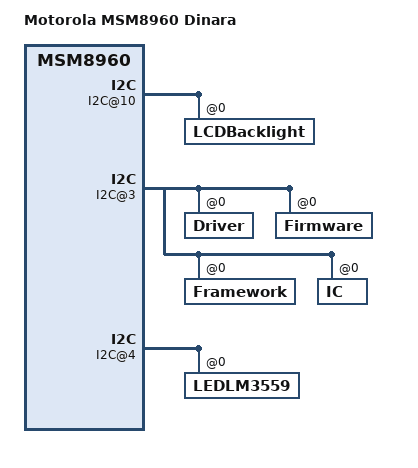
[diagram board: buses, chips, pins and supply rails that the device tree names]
/* Copyright (c) 2013 Motorola Mobility LLC. All rights reserved.
 *
 * This program is free software; you can redistribute it and/or modify
 * it under the terms of the GNU General Public License version 2 and
 * only version 2 as published by the Free Software Foundation.
 *
 * This program is distributed in the hope that it will be useful,
 * but WITHOUT ANY WARRANTY; without even the implied warranty of
 * MERCHANTABILITY or FITNESS FOR A PARTICULAR PURPOSE.  See the
 * GNU General Public License for more details.
 */

/dts-v1/;

/include/ "skeleton.dtsi"

/include/ "msm8960.dtsi"

/include/ "msm8960-motref.dtsi"

/include/ "msm8960-motref-pinmux.dtsi"

/ {
	model = "Motorola MSM8960 Dinara";
	compatible = "mmi,msm8960-qinara";

	mmi,product = "mmi,msm8960-dinara";

	mmi,dt_revision = <2>;

	Aliases@0 {
	};

	Machine@0 {
	};

};


/ {

	Aliases@0 {
	};

	Chosen@0 {
		batt_eprom_gpio = <0x5d>;
		emu_id_activehigh = <0x01>;
		emu_id_flt_activehigh = <0x01>;
		emu_id_flt_gpio = <0xaa>;
		emu_id_mpp_gpio = <0xcd>;
		factory_kill_disable = <0x00>;
		factory_kill_gpio = <0x0000004b>;
		formfactor = <0x00000003>;
		last_compat_version = <0x01330684>;
		product = <0x000015ff>;
		version = <0x0133068b>;
	};

	Machine@0 {
	};

	System@0 {

		ClockTree@0 {
			class = [436c6f636b5472656500];
			type = <0x001e0014>;

			Clock@0 {
				class = [5175616c636f6d6d436c6f636b54726565436c6f636b00];
				clock = <0x000c>;
				clockname = [636f72655f636c6b00];
				deviceid = [6d736d5f73657269616c5f68736c2e3500];
				type = <0x001e0015>;
			};

			Clock@1 {
				class = [5175616c636f6d6d436c6f636b54726565436c6f636b00];
				clock = <0x000e>;
				clockname = [69666163655f636c6b00];
				deviceid = [6d736d5f73657269616c5f68736c2e3500];
				type = <0x001e0015>;
			};

			Clock@2 {
				class = [5175616c636f6d6d436c6f636b54726565436c6f636b00];
				clock = <0x0025>;
				clockname = [63616d5f636c6b00];
				deviceid = [342d3030333600];
				type = <0x001e0015>;
			};

			Clock@3 {
				class = [5175616c636f6d6d436c6f636b54726565436c6f636b00];
				clock = <0x0024>;
				clockname = [63616d5f636c6b00];
				deviceid = [342d3030343800];
				type = <0x001e0015>;
			};

			Clock@4 { /* gsbi4_uart_clk, core_clk, msm_serial_hs.1 */
				class = [5175616c636f6d6d436c6f636b54726565436c6f636b00];
				clock = <0x0009>;
				clockname = [636f72655f636c6b00];
				deviceid = [6d736d5f73657269616c5f68732e3100];
				type = <0x001e0015>;
			};

			Clock@5 { /* gsbi4_p_clk, iface_clk, msm_serial_hs.1 */
				class = [5175616c636f6d6d436c6f636b54726565436c6f636b00];
				clock = <0x000b>;
				clockname = [69666163655f636c6b00];
				deviceid = [6d736d5f73657269616c5f68732e3100];
				type = <0x001e0015>;
			};

			Clock@6 { /* gsbi4_p_clk, iface_clk, qup_i2c.4 */
				class = [5175616c636f6d6d436c6f636b54726565436c6f636b00];
				clock = <0x000b>;
				clockname = [69666163655f636c6b00];
				deviceid = [7175705f6932632e3400];
				type = <0x001e0015>;
			};
		};

		EMUDetection@0 {
			accy-support = <0x00>;
			class = [5175616c636f6d6d5f454d555f446574656374696f6e00];
			ic-type = <0x00>;
			type = <0x0000001d>;
			uart-gsbi = <0x04>;
			usb-otg-vreg = [383932315f7573625f6f746700];
			vdd-vreg = [454d555f504f57455200];
			vdd-vreg-mv = <0x00286f90>;

			Gpio-alt-mode@0 {
				class = [4750494f00];
				gpio-info = <0x0211>;
				pin-name = [53454d555f414c545f4d4f44455f454e5f4750494f00];
				pmic-gpio-cfg = [010000050603000001];
				pmic-gpio-cfg-alt = [010001050601000000];
				type = <0x001e0010>;
			};

			Gpio-dminus@0 {
				class = [4750494f00];
				gpio-info = <0x0215>;
				pin-name = [444d494e55535f4750494f00];
				pmic-gpio-cfg = [010000010602010000];
				pmic-gpio-cfg-alt = [020000040603000000];
				type = <0x001e0010>;
			};

			Gpio-dplus@0 {
				class = [4750494f00];
				gpio-info = <0x0229>;
				pin-name = [44504c55535f4750494f00];
				pmic-gpio-cfg = [020000010602010000];
				pmic-gpio-cfg-alt = [020000000603000000];
				type = <0x001e0010>;
			};

			Gpio-id-en@0 {
				class = [4750494f00];
				gpio-info = <0x0309>;
				pin-name = [454d555f49445f454e5f4750494f00];
				pmic-mpp-cfg = [000400];
				pmic-mpp-cfg-alt = [010401];
				type = <0x001e0010>;
			};

			Gpio-id@0 {
				class = [4750494f00];
				gpio-info = <0x030a>;
				pin-name = [454d555f49445f4750494f00];
				pmic-mpp-cfg = [030200];
				type = <0x001e0010>;
			};

			Gpio-mux-ctrl0@0 {
				class = [4750494f00];
				gpio-info = <0x016b>;
				msm-gpio-cfg = <0x00030300>;
				pin-name = [454d555f4d55585f4354524c305f4750494f00];
				type = <0x001e0010>;
			};

			Gpio-mux-ctrl1@0 {
				class = [4750494f00];
				gpio-info = <0x0160>;
				msm-gpio-cfg = <0x00030100>;
				pin-name = [454d555f4d55585f4354524c315f4750494f00];
				type = <0x001e0010>;
			};

			Gpio-ppd-det@0 {
				class = [4750494f00];
				gpio-info = <0x0223>;
				pin-name = [53454d555f5050445f4445545f4750494f00];
				pmic-gpio-cfg = [020000050603000000];
				type = <0x001e0010>;
			};

			Gpio-sci-out@0 {
				class = [4750494f00];
				gpio-info = <0x015a>;
				msm-gpio-cfg = <0x00030000>;
				pin-name = [454d555f5343495f4f55545f4750494f00];
				type = <0x001e0010>;
			};

			Gpio-uart-rx-pair@0 {
				class = [4750494f00];
				gpio-info = <0x022a>;
				pin-name = [52585f504149525f4750494f00];
				pmic-gpio-cfg = [010000010202010000];
				pmic-gpio-cfg-alt = [020000050202000001];
				type = <0x001e0010>;
			};

			Gpio-uart-tx-pair@0 {
				class = [4750494f00];
				gpio-info = <0x0216>;
				pin-name = [54585f504149525f4750494f00];
				pmic-gpio-cfg = [020000010202010000];
				pmic-gpio-cfg-alt = [020000050202000001];
				type = <0x001e0010>;
			};

			Gpio-whisper-rx@0 {
				class = [4750494f00];
				gpio-info = <0x0113>;
				msm-gpio-cfg = <0x01030000>;
				msm-gpio-cfg-alt = <0x00030000>;
				pin-name = [574849535045525f554152545f52585f4750494f00];
				type = <0x001e0010>;
			};

			Gpio-whisper-tx@0 {
				class = [4750494f00];
				gpio-info = <0x0112>;
				msm-gpio-cfg = <0x01030000>;
				msm-gpio-cfg-alt = <0x00030002>;
				pin-name = [574849535045525f554152545f54585f4750494f00];
				type = <0x001e0010>;
			};
		};

		GSBISetup@0 {
			class = [47534249536574757000];
			type = <0x001e0012>;

			GSBI@1 {
				class = [5175616c636f6d6d47534249504f525400];
				gsbi_type = <0x03>;
				max_clock_speed = <0x00e5cc20>;
				type = <0x001e0013>;
			};

			GSBI@10 {
				class = [5175616c636f6d6d47534249504f525400];
				clk_freq = <0x00061a80>;
				gsbi_type = <0x01>;
				src_clk_rate = <0x016e3600>;
				type = <0x001e0013>;
			};

			GSBI@3 {
				class = [5175616c636f6d6d47534249504f525400];
				clk_freq = <0x00061a80>;
				gsbi_type = <0x02>;
				src_clk_rate = <0x016e3600>;
				type = <0x001e0013>;
			};

			GSBI@4 {
				class = [5175616c636f6d6d47534249504f525400];
				clk_freq = <0x00061a80>;
				gsbi_type = <0x06>;
				shared_mode = <0x01>;
				src_clk_rate = <0x016e3600>;
				type = <0x001e0013>;
			};

			GSBI@5 {
				class = [5175616c636f6d6d47534249504f525400];
				gsbi_type = <0x06>;
				shared_mode = <0x00>;
				type = <0x001e0013>;
				uart_line = <0x00>;
			};
		};

		I2C@10 {
			class = <0x49324300>;
			type = <0x001e0003>;

			I2C,Board@0 {
				class = [435434303600];
				ct406_prox_covered_offset = <0x008c>;
				ct406_prox_pulse_count = <0x03>;
				ct406_prox_recalibrate_offset = <0x0050>;
				ct406_prox_saturation_threshold = <0x0208>;
				ct406_prox_uncovered_offset = <0x0064>;
				i2c,address = <0x00000039>;
				i2c,type = [637434303600];
				irq,gpio = <0x31>;
				prox_samples_for_noise_floor = <0x05>;
				type = <0x00250001>;
			};

			I2C,Board@1 {
				class = [544d5031303500];
				i2c,address = <0x00000048>;
				i2c,type = [746d7031303500];
				irq,gpio = <0x43>;
				type = <0x00030014>;
			};

			LCDBacklight@0 {
				class = [4c43444261636b6c6967687400];
				i2c,address = <0x00000038>;
				i2c,type = [6c6d3335333200];
				type = <0x000b0004>;
			};
		};

		I2C@3 {
			class = <0x49324300>;
			type = <0x001e0003>;

			I2C,Board@0 {
				class = [4359545453503300];
				i2c,address = <0x0000003b>;
				i2c,type = [637974747370332d69326300];
				irq,gpio = <0x2e>;
				type = <0x00040002>;

				Driver@0 {
					class = [44726976657200];
					touch_driver_flags = <0x0003>;
					touch_driver_name = [637974747370332d69326300];
					type = <0x00000019>;
				};

				Firmware@0 {
					class = [4669726d7761726500];
					fw_image = [00ff38000102030405060700ff390001020304050607002c407d5a70303030307e3030307d715d7e7d71817e7e3030307e3030307d5c317e7e3030307e3030307e303030303030307e3030307e3030307d5baa7e7e303030c30600ff390001020304050607002d7e3030307e3030307e30303030303030303030303030303030303030303030303030303030303030303030303030303030303030303030303030303030303030ea5500ff390001020304050607002e62e3385d047321a0bff75d047321a0bff05d047321a0bfe95018490420afe260ff49c901b01a41d6fe70cf711041045f70cf43d6014070cf71104304a070cf7f624600ff390001020304050607002f30303030303030303030303030303030303030303030303030303030303030303030303030303030303030303030303030303030303030303030303030303030008300ff390001020304050607004850007c4dbb210262d00153025102a01d62d00855010162d006553d0055370062d0002e0b0462d000510b60087c1ef67c26677c1b897c260b7c260c7c260d7d1530fc00ff39000102030405060700494562d00155020055030062d0065555005155a0077c1b897c2c88578e50007c14dc62d000518e7c4e2862d00553f77c214262d0065544007c20fa530262d00651ef7b00ff390001020304050607004a43a0375134645c62d3053dbc00b0043dbd29d0055140a00650007c3ec150027c218051027c15df78c01050007c3ec162d006514962d001530250017c3ec162d0dd5800ff390001020304050607004b06514962d0013a02a01962d0065149a01262d0015102a00b62d00676553c5501cf6f62d00151027c4ed762d00151027c16bc62d00151027c17c5510262d0063aee7b00ff390001020304050607004c49a00d3c4001b008514962d001530262d0063c56ffb0037a493c51ffb00662d0017a0262d006514962d00158027c152262d001530362d0063c56ffb00376493c8fbe00ff390001020304050607004d51ffb00662d001760262d001510257037c2a0762d001510262d006534951473a4ea00447120162d00151027c2b0c62d00151027c2a3550037c2aef51037f5302606100ff390001020304050607004e51027c2c1f62d00151027c277451027c277562d00151027c260e62d00151027c26f351027c295a51027c295b62d00151027d298d530262d006510f2170b01562768e00ff390001020304050607004fd0013c0201b02962d0065552015548017d13ef50007c4dbb218062d00553fe62d000260bfb62d000510b60087c38f462d00151027f7c5d9d508857137c563c620cbb00ff3900010203040506070050d00555ff017c566a62d006535e62d00055760462d00055770262d0005578017c5f597c615c78c02b71105de070cf62d0015302711041e0e743e01870cf62e33825ee00ff39000102030405060700517c47b562e33862d0015102711060e07d14557c6cfe70cf7f7f7c26f47c14dd7c146e7c1b637c1b627c1b5b7d20e362d0065554005553007c3e9f7c3e3d501f574a3900ff3900010203040506070052017c4d8f7c57ab62d0065547003c47f0d0445700500b4b02474b090060d35600005700500a4b02474b090060d35600005700500c4b02474b090060d352000857f69200ff390001020304050607005300500e4b02474b090060d318540076473c47f0cfbe50005347534e7f7f7c693a70fe62d00055bf0062d00055c00062d00055bd0062d00055be0171017c3af2624b3d00ff3900010203040506070054d0065550f47c68e87c5b677c5b5f62d00555ea0055eb00500053de53df53e053e17f5a043a04a017510462d00653323900a00962d00151047c415050017f5104ffa600ff390001020304050607005557007d394362d006510f21703910b01350197c4dbb21f0a00a7c3a6e62d00555ef0162d00551f3b02762d006470f70b01f501b7c4dbb78c017501b57007c4d8f443100ff390001020304050607005662d00555f3017c454062d00855010162d00855030062d00855020062d0063c4702c02062d0083c0110a01162d008510162d00553f462d00855011062d00555f2320e00ff3900010203040506070057007f62d0083c0110b01562d00576f23cf21bc00b55f20051f462d00853017f530462d00655390062d0015104a0c95797500660d3520053055700500a4b02054b94d300ff3900010203040506070058090060d35200530657017d164a551e00551f03510557007c47c101974b090660d3520053075700500a4b02074b090060d352003a06d0115700500a4b02074b09606c00ff39000102030405060700590060d3520053065805755a055b3a04cfbd70fb6e065507005505005700500a4b02054b090060d33d000ac0155700500a4b02054b090060d352003a06d0037607db6300ff390001020304050607005a76053c05f0cfd555060057007d16a162d3053dd101b0070606287d16a0060614755b3a04cfea51063a07d00b62d0065140b00455390162d00651397f3906c003463a00ff390001020304050607005b50055700530462d303520062d302540062d3035600ff755b3910cfeb62d0015505005506c450007d170e0851050858061860d3185200785307510b3c0710d008e87f00ff390001020304050607005c580762d30354000606080e050074530b3a04cfd7550c0057007d173b62d306522062d0015a085c62d3033d00ffa00a580c62d3065420760c5808755b62d0063a423400ff390001020304050607005d4fcfda62d001550700580c5b3904d05e5509ff5a085b62d0063a5ed03f62d00151083a04d0367d179657007d177862d30652203a07a007755b3a08cff25b3a080cc900ff390001020304050607005eb013580762d3033d00ffa0095f090776077d179b76073c0710cfcf62d0015808510962d3065420755b3904cfa451043905c003500462d0063a5ea0037204d0034a4600ff390001020304050607005f515e534f7f3906c0035005550f005510c45520007d1b50510f581060d35200531f510f58104b01064b090060d35200085201530c18530b510f58104b01044b095f7100ff39000102030405060700600060d35200085201530a1853097a1f5f0d0b5f0e0c650e6b0d5f11095f120a65126b11581f62d3023d00ffa2195f221f55210065226b21512201c85c51210901ee9000ff390001020304050607006160d352000852015316185315510c12164b510b1a154b7c3b3f5a1753185f221f55210065226b21512201d85c5121090160d352000852015314185313510a1214d45d00ff39000102030405060700624b51091a134b7c3b3f5a19531a5f2b1a5f2a195529005528005f2f1a5f2e19552d00552c007c40e45f05285f06295f072a5f082b5f2b185f2a175529005528009ef200ff39000102030405060700635f2f185f2e17552d00552c007c40e4512b0408512a0c0751290c0651280c053c0890510719015106190051051900d0a15f221f55210065226b21512201a85c51a1f900ff390001020304050607006421090160d35200085201530e18530d50015f210d5f220e70fb6e216e2278bffa510c12225324510b1a2153235124040e51230c0d5f0b0d5f0c0e70fb6e0b6e0c83be00ff39000102030405060700655f221f55210065226b21512201b85c5121090160d35200085201531218531150015f21115f221270fb6e216e2278bffa510a1222532451091a21532351240412ba2d00ff390001020304050607006651230c115f09115f0a1270fb6e096e0a511f6401285c62d30552000852015316185315511f6401685c52000852015314185313510c12164b510b1a154b7c3b3fcf5800ff39000102030405060700675a1d531e510a12144b51091a134b7c3b3f5a1b531c511f645c52493a1e52481a1dc00f511f645c52893a1c52881a1bd088511f645c564800564901511f645c56df7900ff3900010203040506070068880056890162d0065147a01862d001511f645c564800564903511f645c56880056890462d001511f645c510b08510c5429185428511f645c510908510a5469187bb200ff390001020304050607006954687d1a78511f645c62d30556480056490c511f645c568800568906511f645c510b08510c5429185428511f645c510908510a54691854685f221f55210065228ed900ff390001020304050607006a6b21512201a85c5121090160d3510d08510e54011854005f221f55210065226b21512201b85c5121090160d3511108511254011854005f221f55210065226b21505e00ff390001020304050607006b512201c85c5121090160d3510b08510c54011854005f221f55210065226b21512201d85c5121090160d3510908510a5401185400511f6401285c62d305520008b42700ff390001020304050607006c52015f210f5f22100622060e21000851210858221860d3185401185400511f6401685c62d30552000852015f210f5f22100622040e21000851210858221860d3322400ff390001020304050607006d1854011854000610080e0f005104762053043a20a0037204cc7e7f62d00555f8047f7f570062d3035600ff755b3910cff562d006554f00554900554c0050007cc04100ff390001020304050607006e4ed762d000558e007f554000471201a3067c60257c5f5962d0065f4e477c57c362d001530462d0065134645c62d00651dd0862d00651de62d30554bd1854bc62f9b400ff390001020304050607006fd0015104a22e62d00655430162d001470404a01c62d00655470362d00655df0162d00655400162d00055972f7d1dea470402b00862d0065139a1e162d006554705cd00ff39000102030405060700700262d0002e160262d00055972f7d1ccb62d00655390062d00655df0062d0065134b01f2e3601512a582b7c459562d0065f282a5f292b55340151347c45e17d1c88d400ff3900010203040506070071a73c3401b01f2e3602512c582d7c459562d0065f2a2c5f2b2d55340251347c45e17d1ca73c3402b01f2e3604512e582f7c459562d0065f2c2e5f2d2f55340351c95700ff3900010203040506070072347c45e17d1ca73c3403b01c2e3608512858297c459562d0065f2e285f2f2955340051347c45e171807c57c362d001530462d0065134645c62d00651dd0862d093ec00ff39000102030405060700730651de62d30554bd1854bc62d0063c360fd00962d001470402bf3662d0065139bf2f3c360fd00962d001470402a0fc62d0065f353455340062d0015505015105424b00ff3900010203040506070074645c52bc530852bd530962d0065134645c62d00151093bbd51081bbcd008510562d006533462d00176053c0504cfd062d00651353a34a0b351347c45e162d006230e00ff390001020304050607007555df00718062d0065134b014512858297c459562d0065f30285f31297d1da43c3401b014512a582b7c459562d0065f302a5f312b7d1da43c3402b014512c582d87d700ff39000102030405060700767c459562d0065f302c5f312d7d1da43c3403b011512e582f7c459562d0065f302e5f312f5135b00a5f28305f29317d1dea3c3501b00a5f2a305f2b317d1dea3c1c0200ff39000102030405060700773502b00a5f2c305f2d317d1dea3c3503b0195f2e305f2f317d1dea55470162d00055972a62d00655360062d0002e16027d1e0e62d00655430055360062d00055d57500ff3900010203040506070078971962d00655470062d0002616fd62d006514d62d0003a16a0dc62d000511662d006534d62d000471602a064500857037c60b062d0015504005700500e4b020499fe00ff39000102030405060700794b090060d3520053085700500c4b02044b090060d352001208085700500b4b02044b090060d31854005700500c4b02044b090060d3520008570050094b02044b5a8100ff390001020304050607007a090060d318540076043c04f0cfac7f500457027d60b055470062d0002616fd62d0003c7604a008500457027c60b062d0065112210162d001530651073a06a0360de800ff390001020304050607007b62d0065134a02a50007c45e1718062d006512858297c459562d0065f30285f312955360055340055350062d00055971962d00151067f62d006470f70b15470fee9a100ff390001020304050607007c62d00051bf0862d00051c062d0015304185303710162d006470f02a0497c34217c38cc70fe62d00051bf0862d00051c062d00553eb1853ea7101500053de53dfab2600ff390001020304050607007d53e053e17c6025508857137c563c7c6cfe7c366762d001510308510462d00553e31853e27f5110210f62d001530562d0063c50f1b0645115a0047c357962d001201100ff390001020304050607007e510458033c0500a00b62d00553e35ae27d206362d006470f04a03562d001510462d00512e362d0015307510362d0051ae262d0015306510762d0053ae962d001e59c00ff390001020304050607007f510662d0051ae8c09b7c33c77d206362d00553e35ae27d20633c50f2b03762d0015105b01062d000510fb00962d006470f04b0177c366762d001510308510462bb4900ff3900010203040506070080d00553e31853e27d20635116a0567c35797d20637c38cc70fe62d00051bf0862d00051c062d00553eb1853ea7101500053de53df53e053e17c3af27c366762d0a31a00ff390001020304050607008101510308510462d00553e31853e27d20633c50f4a00e500157007c68f062d0065550f462d006470f70b07870fe62d00051bf0862d00051c062d001530418530300d500ff39000102030405060700827101510462d00512eb62d0015307510362d0051aea62d0015306510762d00504e162d001510662d0050ce050000cdf0cde62d001510308510462d00553eb1853ad3000ff3900010203040506070083ea3ce13051e0197551df190051de1900c0117c38cc500062d00553de53df53e053e17f62d0085501017c578c3978c00671807c454071807d3df2264c9f7c6e720bed00ff390001020304050607008462d001530462d0065f515662d001510462d00653563c4702d01e62d00151047c36c362d00153055105a00862d0065145a00650047c2ca850047c3ff562d00151ca6c00ff3900010203040506070085047f51f7b01e62d00155040057b050064b02044b090060d356000176043c0405cfeb7f62d00155040057b050064b02044b090060d356000076043c0405cfeb7fb84900ff390001020304050607008662d0015304580462d30152003906c0035005530b3900a4615507005508005510005509007d23e95109640209530f580962d30552d1a0a155160055173350035f4c7200ff3900010203040506070087120955110065126b1178bffa511201ca5c5111090060d35200531352015314511458137c3da8580962d30554cc55160055175550035f120955110065126b1178f5c500ff3900010203040506070088bffa511201c85c5111090060d35200531352015314511458137c3da8580962d306541b580962d3053dcc14b00558097bcc580962d3063d1b0cb00558097b1b58a62800ff39000102030405060700890962d30552cc570c7c404d580962d306031b530a7d2291579550064b020f4b090060d35200580962d30554cc579650064b020f4b090060d35200580962d30654ae3900ff390001020304050607008a1b579750064b020f4b090060d35200530a5505005506003c0a0cc01457f350094b020a4b090060d3520004060e05003c0a0dc01457f450094b020a4b090060d365a800ff390001020304050607008b520004060e05003c0a0ec01457f550094b020a4b090060d3520004060e05003c0a02c01457ff50094b020a4b090060d3520004060e05003c0aefd0145701500a6cb700ff390001020304050607008c4b020a4b090060d3520004060e05003c0ae5d014570b500a4b020a4b090060d3520004060e05003c0ae4d014570c500a4b020a4b090060d3520004060e05003cb95200ff390001020304050607008d0ae3d014570d500a4b020a4b090060d3520004060e05005109645c510508510662d30554b31854b251083a0651071a05d00a5f07055f08065f0e0962d0065149140900ff390001020304050607008ea06362d001580962d006513a62d306131b62d00153125511001e1100511258117c3b3f5a13531451143903511331801980d032580962d006513b62d30513cc6277d000ff390001020304050607008fd00153125511001e1100511258117c3b3f5a13531451143903511331801980c00455100162d001760951093a0bcdb962d0065149a02d62d0015110a01d62d006d99500ff39000102030405060700903c3302d015763350007c3ec162d006514962d001530b7d242562d0065533007d242555330062d001580e62d0065133b1b462d001510b62d0063a49a1a862d00181e600ff39000102030405060700915509007d25dc5b531151093a11a189510e011b5c62d30652005809131b53125511001e1100511258117c3b3f530a3c0a03d165551e00551f07510e645c62d3053c5d00ff390001020304050607009252b2531152b35312511258117c47c15a135314500370fb6e136e1478bffa5109645c52b33a1452b21a13c01162d0063cdd00b00762d0063cde29c11c62d00158426a00ff390001020304050607009309755a0c7d25bc5a0d5a0c060dff50035f120c55110065126b1178bffa511201c75c5111090060d352000850035f140d55130065146b1378bffa511401c75c51375500ff390001020304050607009413090060d318540050035f120c55110065126b1178bffa511201c85c5111090060d352000852010850035f140d55130065146b1378bffa511401c85c511309004a7c00ff390001020304050607009560d318540118540050035f120c55110065126b1178bffa511201ca5c5111090060d352000852010850035f140d55130065146b1378bffa511401ca5c511309009f2700ff390001020304050607009660d3185401185400510c6401b25c62d305520008520108510d645c1854b31854b2510c01cc5c5200580d54cc510c011b5c62d3065200580d541b760c580c5b3a345200ff39000102030405060700970bcf0551097c55e362d00151093a0ed0037a0e7a097a0b62d0017609580e51093a0bce6362d30552cc62d006533b62d306521b533a7d25fe62d00655330062d0f2cf00ff390001020304050607009801510b580462d30154007f7f7f7f530362d006510f21703900b00b62d0015103a0457d3bb83910a03e3920b0323c5606c00c514c21f0290f53107d2657514921529000ff39000102030405060700990f62d001530562d006514c21f062d0012a0562d0065310500258107d4d8f470f40a0047d3b587f62d006510f217062d00153037c34e662d006470f01a01b7c4db45500ff390001020304050607009a1a70cf62d40062d50062d10062d30062d00062e338500000718062d006510f217062d00153043a03a015510358047c496d7c3cef62d001510358047c498262d0a83e00ff390001020304050607009b065152a02e3c4801b02050007c4dbb218062d00553fe62d000260bfb62d000510b60087c38f47d26ec7c33ff62d0065552007f7f4109fb41e0ef62daef62d000911100ff390001020304050607009c2e0b0462d000510b6008711043090443080470cf62d006554100550f085510005511005513005514015515005517ff55160055120155180055190062d00555fe76dc00ff390001020304050607009d0062d0065552005548007c3da271807c3cef62d000260bfb62d000510b600850f457017c563c62d0002e0b0462d000510b60087f7f550af05509075503005504355b00ff390001020304050607009e0062d006510f62d0015308260870470840a1c662d0065154b00e5114210753545154b004555401475401a0e755530062d0013c0850b01055050a55060062d006d59c00ff390001020304050607009f2654fe7d29053c0840b01055050c55060062d0062654fe7d29053c0870b02762d006474140a01362d00155050c55060062d0062654fe7d290562d00155050e5500f300ff39000102030405060700a006007d290562d006474140a043500757287c4d8f62d001550700573950014b02074b090060d352005c500802077c4d8f62d00176073c0728cfe1550930550a28549c00ff39000102030405060700a155050155066b62d0062654fe7d29055134b00a62d00155030a55040062d0063c3401b00a62d00155031155040062d0063c3402b00a62d00155030f55040062d08a0900ff39000102030405060700a2063c3403b08062d00155030d5504007d2905475402a02255530162d0013c0870a0063c0860b00962d006474140a05762d0062654fd7d2905475404a022555302931c00ff39000102030405060700a362d0013c0870a0063c0860b00962d006474140a03162d0062654fb7d290555540055530362d001550700500008500e085107640107087c4da338fd62d0017607d19900ff39000102030405060700a43c070ccfe650007d294251032a04a017510358044b02074b0900285c510902077c4d8f7d293c510558064b02074b090060d352005c510902077c4d8f62d001516acc00ff39000102030405060700a5077462d00153073a0acfc062d0065154a00762d00555ff007f7f7f62d006510f21703910b02762d0053cef01b01f55ef00501958ee7c4d8f501a62d00558ed7c8f1700ff39000102030405060700a64d8f501b62d00558ec7d4d8f7f530362d006510f62d00153042604703c0410b0137c47ed62d0015305510521df5c50017d4d8f5104b0055103b00b3c0420a00675e400ff39000102030405060700a7470440a0425104b01962d006513464642a412a475c50017c4d8f62d0065f3c347f7c3bb262d001530662d0065134646462d0012a0662d0062a415c50017c4d8ffcf300ff39000102030405060700a862d0065f3c347f3900b00862d006264cef7f62d006474c10a00762d30156000051443900a00f474c10b00a62d3015600012e4c107f3900b0af62d0065134a0a3a54600ff39000102030405060700a9513c3a34b09d51346401bd5c62d305520062d00153053c050ed00a62d006513d747d2a66500062d006533d3965c06c5f3534553d0062d0002616fd500457027ca24100ff39000102030405060700aa60b050007c45e1718062d006512858297c459562d0065f30285f31293c3501b00a5f2a305f2b317d2ac33c3502b00a5f2c305f2d317d2ac33c3503b0075f2e30244600ff39000102030405060700ab5f2f317c612d62d0065536005534005535007c57c362d001530562d006513d7d2ae950007d2ae9500062d006533d7f62d001530450007c4dbb62d00153054705c28300ff39000102030405060700ac03a009580462d3015600007f3900b10f62d0063c37c9d00376373c37c9c10051383a34b0067a377d2c147c60257c5f5962d00651387c45e171807c57c362d0016ad400ff39000102030405060700ad53053c0503d0ad62d0065138b014512858297c459562d0065f30285f31297d2ba63c3801b014512a582b7c459562d0065f302a5f312b7d2ba63c3802b014512c224500ff39000102030405060700ae582d7c459562d0065f302c5f312d7d2ba63c3803b011512e582f7c459562d0065f302e5f312f62e33862d0002616fd7c612d62d0002e160262d0065138b00b5158b200ff39000102030405060700af2858297c45957d2bf33c3801b00b512a582b7c45957d2bf33c3802b00b512c582d7c45957d2bf33c3803b008512e582f7c459562e33862d00651347c45e17180356d00ff39000102030405060700b07c612d7c57c362d00153057c5fef62d00655370076383c3804c0045538007f530362d0065148a004554800510f62d00153042604703c0410b0207c47ed62d0019e4000ff39000102030405060700b15305510529205c50017c4d8f7d2c5262e3387c4d7778dff87f5104b0055103b00b3c0420a006470440a01d62d006064140514129205c50017c4d8f7d2c8162e3f7f300ff39000102030405060700b2387c4d7778dff87f62d006510f217062d00153047c60257c33fc7c34b962d0015104b0047d5fef7f5c62d3013d0006c004560005520062d0015a06530d3900b0b67200ff39000102030405060700b31d62d00055ed0062d00055ee0062d006554200554500554a1e554b0f7f62d0063c4201b00a554a28554b0a7d2cff3c4501b007554a147d2cff554a1e554b0f7c60c700ff39000102030405060700b455d262d001550b0057007d33b055100062d006553e00500062d00553d653d753d853d9500053da53db53dc53dd62d00655240055250062d00155140057955006e5d200ff39000102030405060700b54b020b4b090060d352005308579650064b020b4b090060d352005309579750064b020b4b090060d352005307570750074b02074b090060d3520021c029400857b67500ff39000102030405060700b60750074b02074b090060d31854005700500a4b02074b090060d35200530f3c0f29c021551c00551d0a5f160f55150065166b1565166b15511658157c43db5313dfc800ff39000102030405060700b77d2ddb551e00551f09510f57007c47c1551c00551d0a7c43db531376105700500a4b02074b090060d35113030053165515000e15005115318039807204b0055158bb00ff39000102030405060700b80f3a16d16e510a745f120b0612057d2f09579550064b02124b090060d352003a07b0e1510e747d2eed5311530c0611ff50035f160c55150065166b1578bffa51061800ff39000102030405060700b91601c75c5115090060d352000850035f181155170065186b1778bffa511801c75c5117090060d318540050035f160c55150065166b1578bffa511601c85c5115a65900ff39000102030405060700ba090060d352000852010850035f181155170065186b1778bffa511801c85c5117090060d318540118540050035f160c55150065166b1578bffa511601ca5c5115d1b000ff39000102030405060700bb090060d352000852010850035f181155170065186b1778bffa511801ca5c5117090060d3185401185400510c743a0dcf39510e7c55e362d0015514017a0e1612f5f900ff39000102030405060700bc037a0d510e74061203530e3a0dcf0351083900a012531c061cff5f1d0950f4020757007c406662d00151083913a011531c761c5f1d09500c020757007c40666260d000ff39000102030405060700bdd0015109a0135f1c0850ff0209531d50ff020757007c406662d0013c090ba0135f1c0850010209531d5001020757007c406662d006513ea0527a3e513e62d001871f00ff39000102030405060700be531655150065166b15511601075c5115090760d35200213f530862d006513e62d001531655150065166b15511601085c5115090760d35200213f53095108570c56be00ff39000102030405060700bf7c404d020953077d2ddb62d001580a511062d0063a4aa0037204d02762d0003ced01d025500062d00076ed62d0003cee00b01662d00055ee0162d001550d007d953d00ff39000102030405060700c0300862d00055ed0062d0063a4aa0037204d0075544017d33a962d0013c1400b00c62d0063a4ba0037204d37862d006553e00500062d00553d653d753d853d950f70200ff39000102030405060700c10053da53db53dc53dd62d006552400552500579550064b62d001020b4b090060d352005308579650064b020b4b090060d352005309579750064b020b4b090060062100ff39000102030405060700c2d352005307570750074b02074b090060d3520021c0298008570750074b02074b090060d318540062e3385700500a4b02074b090060d35200531f551e00510857dfd400ff39000102030405060700c3007c47c15a155316511662d00504d962d001511562d0050cd850000cd70cd65700500a4b62d00102074b090060d35200531f551e00510957007c47c15a155316a35d00ff39000102030405060700c4511662d00504dd62d001511562d0050cdc50000cdb0cda5700500a4b62d00102074b090060d3520062d00604250e24005700500a4b62d00102074b090060d351082800ff39000102030405060700c513030053165515000e15005115318039807204b005510f3a16d06451083900a012531c061cff5f1d0950f4020757407c406662d00151083913a011531c761c5f337f00ff39000102030405060700c61d09500c020757407c406662d0015109a0135f1c0850ff0209531d50ff020757407c406662d0013c090ba0135f1c0850010209531d5001020757407c406662d0ac7200ff39000102030405060700c706513ea0527a3e513e62d001531655150065166b15511601075c5115090760d35200213f530862d006513e62d001531655150065166b15511601085c511509075acf00ff39000102030405060700c860d35200213f53095108570c7c404d020953077d30aa55420162d001580a62d00551da62d001532862d00551db62d001532962d00551dc62d001532a62d00551ad7600ff39000102030405060700c9dd62d001532b552c00552d00552e00552f557c40e45f1c285f1d295f1e2a5f1f2b62d006512562d001532362d006512462d00153225521005520007c41e65f15d3c300ff39000102030405060700ca1e5f161f06162a0e15005b5318551700500365186b1778bffa50ca0218531a50000a175319511960d5511a530051153f0051163f0062d00551d662d00153286264e600ff39000102030405060700cbd00551d762d001532962d00551d862d001532a62d00551d962d001532b552c00552d00552e00552f337c40e45f1c285f1d295f1e2a5f1f2b62d006512562d001246700ff39000102030405060700cc532362d006512462d00153225521005520007c41e65f151e5f161f0616190e15005b5318551700500365186b1778bffa50c80218531a50000a175319511960d5a76e00ff39000102030405060700cd511a530051153f0051163f0062d00051957d335b62d0066e246e2578dff762d0063c2401b0043c2500c0075524005525ff500362d0015f160a55150065166b15a87100ff39000102030405060700ce78bffa511601c75c5115090060d362d0065125540062d001580a62d30556d1017d33a962d30556d10062d001060b03755a0a5b3a0dc957510d580662d3015400399400ff39000102030405060700cf62d0065f45447f62d0065550f262d00551e60851e762d0065327185326512758267c68f070fe62d006512608512762d00053be1862d00053bd71017f7d612d62c1a500ff39000102030405060700d0d000260bfb62d000510b6008500357007c563c62d0002e0b0462d000510b60087f711041ecfe70fe7c466e71105de070cf62d0015309711041e0e743e01870cf67f200ff39000102030405060700d162e33862dabf43e040711043d72043e04070cf7c68ec41e6fe7c5b6362dbfe7c44c8711043c98070cf7c0b804062e338711041c97f70cf62dabf5de062d0015341a700ff39000102030405060700d20a5dda220aafdc711041d7df41e0bf7c44d57c5b5f43e6017c68e862d0005500ff62d006260ffd41e0bf62d0015109711060e07c44e071017f62d0083c0101b0e8f600ff39000102030405060700d30b7c6cfe62d0085501047f62d0083c0104b01362d008510362d0083a02d00762d0085501017f62d006510f217062d001530550007c4dbb62d001530651062170297900ff39000102030405060700d43930b00e500062d006580f7c4d8f7d3518510662d006530f62d00151053900b024501e7c4dbb62d0065311501f7c4dbb62d0065312470f02a03f510f21fd5c503ea400ff39000102030405060700d5007d4d8f3910b03150027c4dbb78d029501c7c4dbb62d0065314501d7c4dbb62d0065315501f7c4dbb62d0065316501e7c4dbb62d00653177f62d00155090071934f00ff39000102030405060700d61041ecfe70fe7c466e71105de070cf62d001530a711041e0e743e01870cf62e3387d36147c4d7778d06762d0015109b06062d0003c00ffa0587c46c062d00651a97c00ff39000102030405060700d726582762d001530b5a0c060cfe0e0bff510c62d0003a0062d001510b1900c02e711043d72043e04055090170cf7c5b6362dbfe711043c98070cf7c0b8071104169fd00ff39000102030405060700d8d7df41e0bf41c97f70cf7c5b5f7c47b1710170fe62d00051c062d00512e562d001530c62d00051bf62d0051ae462d001530b510c62d0063a2762d001510b62d0aa8000ff39000102030405060700d9061a26cf6062d001510a711060e07c44e062d00051bf0862d00051c062d00553e51853e471017f62d0065550f15f27155526005115a022512758267c68f070fee4f500ff39000102030405060700da62d006512608512762d00053be1862d00053bd71017d36af500157007c68f070fe62d00055bd0062d00055be01710162d00051bf0862d00051c062d00553e5189a6200ff39000102030405060700db53e47f530662d006470f70a00f470f40b00a55460155450050017f470f40a017514129205c50017c4d8f7d36f062e3387c4d7778dff862d0015515005511005546bb00ff39000102030405060700dc1200550f005510003c0605d1ac5518027d388a570062d301560700755b3908cff5579550064b62d00102184b090060d352005313579350064b02184b090060d351d200ff39000102030405060700dd5200531a579450064b02184b090060d352005316551e00551f0a5700500a4b02134b090060d35200531b511b57007c47c15a1c531d500370fb6e1c6e1d78bffa217300ff39000102030405060700de511d0410511c0c0f62d0063c4601b01a5700500a4b62d00102134b090060d3520070fb6d04100e0f0062d0013c1a13d03a570c500a4b02134b090060d3520053a47a00ff39000102030405060700df0c3c160bd011570d500a4b02134b090060d35200530b5116a011570b500a4b02134b090060d35200530d511aa03a57f450094b02134b090060d3520053083c16dbe900ff39000102030405060700e00bd01157f550094b02134b090060d3520053095116a01157f350094b02134b090060d3520053073c160bd0115701500a4b02134b090060d35200530a5116a011125800ff39000102030405060700e157ff50094b02134b090060d35200530e50005517005514015319511701075c62d301520058143b07d0045f171476143c1408cfe75817520704120e11005607002d8f00ff39000102030405060700e25119743903cfcc061803551e00551f03510657007c47c15a1b531c511b318039807204b00551183a1cce6951123a1051111a0fd004551501511562d0063c460064fe00ff39000102030405060700e3b006534650007f534650017f62d00051270862d000512862d001530a18530970fe7c693a62d001510a58097c68f062daf771017f62d0015505005506197d392f42bb00ff39000102030405060700e450007c4dbb62d00153075107218062d0053afeb02162d001470703b01950e357037c563c62e33862d0017a061e050051052a06bfcc62d0002e0b0462d000510be3fe00ff39000102030405060700e560087f53075a065107a12162d0065111210f62d001530f57007d3a2a62d001510e645c62d3045200531052015311510e01205c62d30652003a11b0b95110b0b52c9100ff39000102030405060700e65508005509c4510e01205c520001005c62d30352005311551000500365116b1078bffa5111040951100c08510858094b01064b090060d35200085201530b1853bfb800ff39000102030405060700e70a510858094b01044b090060d35200085201530d18530c510e6401085c62d30452000852015314185313510b580a7c412c5a105311510f3a1150001a10c03651f32100ff39000102030405060700e80e6401c45c62d30552000852015314185313510d580c7c412c5a105311510f3a1150001a10c00e580e755a0e5b62d0063a32cf2962d006515e62d0013a07d00939ae00ff39000102030405060700e962d006515e7d3a4a510762d006533262d0013a0ea01362d00651327c41505106a00450007f50017f50007f50007f62d00555ee0055ecff55edff7c445962d005762900ff39000102030405060700ea2cee65ee7120628000628400628800628c00629000629400629800629c00711070df5d0053a85d0153a95d0453aa5d0553ab5d0853ac5d0953ad5d0c53ae5d0d5cf600ff39000102030405060700eb53af5d1053b05d1153b17c401a7c430b62d0052cee65ee7c429062d0052cee65ee7c425862d0052cee7c438b7c45407d6cfe62d0063c1679c00455167851167c40bf00ff39000102030405060700ec452153097d3b0f761662d00106090a62d0063c161ad00d62d001510962d0063a15cfe551167c452162d0055ae653e762d00651177c452162d0055ae853e97f53ad9a00ff39000102030405060700ed295a28472880a00c500012295c50001a284b7f512958287f3c5606c00c514c21f0290f53107d3b825149210f62d001530662d006514c21f062d0012a0662d006c0c100ff39000102030405060700ee5310500258107c4d8f57ca500060d35200085201085003087c4da338fd57c8500060d35200085201085005087c4da338fd7f62d00651537f505b570008285306844a00ff39000102030405060700ef187508285307187508285308187528530962d0063c5606c00c514c21f0290f53107d3bfe5149210f62d001531162d006514c21f062d0012a1162d006531050027d3d00ff39000102030405060700f058107c4d8f62d001550d00510d01065c62d3015200530e510d62d0063a5ed09e62d001580d62d3065220530c3910d088510c01005c62d30352005310550a00553bba00ff39000102030405060700f10bc450035f121055110065126b1178bffa5112040b51110c0a510a580b4b01064b090060d3520008520108510e087c4da338fd62d001510a580b4b01044b0900004500ff39000102030405060700f260d35200085201085002020e087c4da338fd500462d001020e5f110a5f120b0612030e11000851110858121860d31859007c4d8f7d3cc3550c0f7d3cc362d00145d000ff39000102030405060700f3550c0f62d001470d01a012510c210f2a0f5c50ff020e7c4d8f7d3ce4510c64646464530f62d001760d3c0d04cf1e7f7c4d1a70cf718062d006510f217062d0014de100ff39000102030405060700f453053900b0075506207d3d0f5506f751067c4d5e500157207c4d8f62d00151053900b037500162d00658417c4d8f500257007c4d8f500857ff7c4d8f501557ff610a00ff39000102030405060700f57c4d8f501e62d00658117c4d8f501f62d00658127c4d8f7d3d613910b0047c46c362d0013c0530a00e62d006510f21f45c50007c4d8f7c47b47c4d0e70cf62d0875700ff39000102030405060700f600260bfb62d000510b60085032570071807c563c62d0002e0b0462d000510b60087f7c4cdb70cf7f53195a18551a00551b0051162a17a03650017d3dc265176b2ea600ff39000102030405060700f71674471680aff7651b6b1a531c51193a1751181a16c00c5117141951161c182e1b0170fb6e166e17511c78bfdb511b581a7f711070df5de070cf62d001530371b1ad00ff39000102030405060700f81041e0e743e01870cf62e33850007d3e235700500c4b02024b0900283908b00a51027453023928cfe962e3385103711060e03c0228b0047c454070cf7f50037c259600ff39000102030405060700f945e171807c6cfe62d006552e83552f10512e582f7c459550027c45e171807c6cfe62d006552c82552d10512c582d7c459550017c45e171807c6cfe62d006552a9c8500ff39000102030405060700fa84552b10512a582b7c459550007c45e171807c6cfe62d0065528845529107f62d000558d0062d00655340055350062d00055150062d0065536005537005538004eea00ff39000102030405060700fb7f3900b09c62d001551700511764646401065c62d30552000852010850035f191755180065196b1878bffa511901ca5c5118090060d31854011854005117646449e100ff39000102030405060700fc6401045c62d30552000852010850035f191755180065196b1878bffa511901c85c5118090060d3185401185400511764646401035c62d30552000850035f1917aca800ff39000102030405060700fd55180065196b1878bffa511901c75c5118090060d318540076173c1705cf6d7f62d00155170050035f191755180065196b1878bffa511901ca5c5118090060d334b900ff39000102030405060700fe52000852010851176464645c1862d305540718540650035f191755180065196b1878bffa511901c85c5118090060d352000852010851176464645c1862d30554c4da00ff39000102030405060700ff0518540450035f191755180065196b1878bffa511901c75c5118090060d352000851176464645c1862d305540376173c1705cf737f5c62d301520062d0083c011d8d00ff390001020304050607010001b0055600007f62d0083c0110b00b390fc00762d00555f4017f51a82104600051a92104600151aa21bb600451ab21bb600551ac2104600851ad21046009620cd60100ff390001020304050607010100620d0062100062110070cf7f531d5a1c5000471d01a003021c651c70fb6e1d3c1d00bfef7f531f5a1e570750074b021f4b090060d3520021c03a1eb0665707fc4e00ff390001020304050607010250074b021f4b090060d307004062d006513e6462d0015320570750074b02204b090060d3520021c02a1c08570750074b02204b090060d3185400762057075007ec2f00ff39000102030405060701034b02204b090060d3520021c02a1d08570750074b02204b090060d318540062d006763e7f50005330533153325333472b01a011512f0433512e0c32512d0c3151fc5000ff39000102030405060701042c0c30652f6b2e6b2d6b2c70fb6e286e296e2a6e2b51282a292a2a2a2bbfd05f28305f29315f2a325f2b337f53165a1551163a1451151a13c00c511658151214de1500ff39000102030405060701054b1a134b7f5114581312164b1a154b7f62d001531357007d41de511601205c62d306520053175116645c511762d3045401560000511701005c62d30352005317117c00ff39000102030405060701065514005515c450035f191755180065196b1878bffa5119041551180c14511458154b01064b090060d35200085201085116645c1862d3045409185408511458159f9900ff39000102030405060701074b01044b090060d35200085201085116645c1862d30554c51854c45816755a165b3a13cf767f5000532453255326532751202a212a222a23a05250017d420865036200ff3900010203040506070108236b226b216b2074472080aff365276b266b256b245328511f3a23511e1a22511d1a21511c1a20c0145123141f51221c1e51211c1d51201c1c2e270170fb6e200e7900ff39000102030405060701096e216e226e23512878bfc35f1c245f1d255f1e265f1f277f62d006553f007c48343c3f01b004513f7f7c47f33c3f01b004513f7f7c48b13c3f01b004513f7f7c520200ff390001020304050607010a48713c3f01b004513f7f7c492b513f7f62d00051092104600062d000510a21bb600462d000510b21046008620c00621000500557007c563c5d0062d006530026988f00ff390001020304050607010b00fb5d04214453015d0821fb53025d0c53035d105304553f005100a007553f017d43085101a007553f017d43085102a007553f017d43085103a007553f017d43540800ff390001020304050607010c085104a004553f01513f7f62d000510929fb600062d000510a2944600462d000510b29fb6008620cff6210ff500557007c563c5d0062d00653002600fb5d0421500100ff390001020304050607010d4453015d0821fb53025d0c53035d105304553f003c00fba007553f017d43883c0144a007553f017d43883c02fba007553f017d43883c03ffa007553f017d4388c4ea00ff390001020304050607010e3c04ffa004553f01513f7f51a87110600051a9600151aa600451ab600551ac600851ad600951ae600c51af600d51b0601051b1601170cf62d0005109600062d0612500ff390001020304050607010f00510a600462d000510b600862d000510c600c62d000510d60107f531f5a1e5000471c80a00e361cff361dff761d0e1c005001471e80a00e361eff361fff761f7a5800ff39000102030405060701100e1e0031015520005521005322511c2a1da03650017d441d651d6b1c74471c80aff765216b205323511f3a1d511e1a1cc00c511d141f511c1c1e2e210170fb6eadbf00ff39000102030405060701111c6e1d512378bfdb512158203c2200a00873744b7309004b7f711050e041e0e743e01870cf62e3387c6025500057607c491762d006553f0062d0015503005700d71400ff3900010203040506070112500a4b02034b090028390cd02f62d006553f0162d0015103570c7c48f362d00553ec55ed0062d00151037d44b462d00576ed110c390ddff67d44c276033c03f0897900ff3900010203040506070113cfbd62d006513f7f500057ff7c496d4309047d496e7c49834109fb50ff57007f70cf62d00551f97110600051fa600451fb600851fc600c51fd601070cf62d000cd0200ff39000102030405060701145109600062d000510a600462d000510b600862d000510c600c62d000510d60107f62d001530a551e00551f05510a57007c47c15a0b530c650c6b0b580b510c7fb7d700ff390001020304050607011570cf7c5fef508857137c563c7c5d9d508857137c563c62d00055760462d00055770262d0005578017c5f5971105de070cf62d0015304711041e0e743e01870cfde2600ff390001020304050607011662e3387c47b562e33862d0015104711060e070cf7f62d0015a0c530b550d005700500e4b020d4b090060d35200530e510b580c4b020d4b60d35200085700500ec2ef00ff39000102030405060701174b020d4b090060d3185400510b580c4b020d4b60d3510e5400760d3c0df0cfc07f62d000531462d000558d0162d0065540013900b01c62d00055720062d00055633200ff3900010203040506070118737862d0005575057c5f597c5d3a7d466b3901b01c62d00055720062d00055736462d0005575057c5f597c5d4c7d466b3902b01c62d00055720062d00055735a9aa100ff390001020304050607011962d0005575057c5f597c5d677d466b3903b01962d00055720062d00055734b62d0005575057c5f597c5d8270cf7f70cf62d00051092104600062d000510a21bbed4800ff390001020304050607011a600462d000510b21046008620c0062100071105d0070cf62d00553f971105d0453fa5d0853fb5d0c53fc5d1053fd4300fb4304444308fb620cff6210ff70cf7f017100ff390001020304050607011b7d4d49500257007c4d8f7c47ed5c50017c4d8f500357147c4d8f5004570c7c4d8f500557007c4d8f7c562370cf62d00051f80851f90850070871807c4da338fdec4800ff390001020304050607011c62d00051fa0851fb085009087c4da338fd62d00051fc0851fd08500b087c4da338fd62d00051fe0851ff08500d087c4da338fd500757a0606c2808755d6c090034d900ff390001020304050607011d2808500f087c4da338fd50160850a4085011087c4da338fd5000085000085013087c4da338fd501808500b085015087c4da338fd501957007c4d8f501a57007c9eae00ff390001020304050607011e4d8f501b57007c4d8f501c62d00658147c4d8f501d62d00658157c4d8f501e62d00658177c4d8f501f62d00658167d4d8f7d4d577f62d006555a197c498f7d6c807300ff390001020304050607011ffe53215a20552200552300472101a009511f0423511e0c22651f6b1e70fb6e206e2151202a21bfe4512358227f62d00551f87f62d000510962d0065300260004c2f800ff390001020304050607012062d000510a21bb290462d006530162d000510b210429fb62d00653025503005504ff5505005506045507fb5508005509ff7d4a0c62d000510962d00653002600109500ff39000102030405060701210462d000510a21bb62d006530162d000510b210462d00653025503ff5504ff5505005506005507005508ff5509ff7d4a0c62d00051092104293362d0065300627f7400ff3900010203040506070122d000510a21bb62d006530162d000510b2104293362d00653025503335504335505335506005507335508335509337d4a0c62d00051092104290b62d006530062837d00ff3900010203040506070123d000510a21bb294462d006530162d000510b2104290b62d006530255030f55040f55050b55064455070b55080f55090f7d4a0c53065a0555080855070051066a94a000ff39000102030405060701246b07650651053a07a0037204c00314077a08bfea51077f62d00153065a05510658057c712e7c4b227d6cfe62d00051092104295162d006530062d000510a21bb16a500ff3900010203040506070125294462d006530162d000510b2104295162d00653025503555504555505515506445507515508555509557d4a0c7f711043ec0270cf62da7f43e08062da6f43e0d92c00ff3900010203040506070126907f7f70cf41e07f62da7f62daef7f62d00055720062d00055734b62d0005575057c5f5950997c6fc87c4ba662e33862d00055720062d00055735a62d000557514a300ff3900010203040506070127057c5f5950997c6fc87c4b6462e33862d00055720062d00055736462d0005575057c5f5950997c6fc87c4ae062e33862d00055720062d00055737862d00055752fda00ff3900010203040506070128057c5f5950997c6fc87d4b2262d00551a829fb7110600051a92104600151aa2944600451ab21bb600551ac29fb600851ad21046009620cff620d006210ff6211522100ff39000102030405060701290070cf62d0065100600051016004510260085103600c51046010500157007c563c71105d0170cf62d0062a05711060015d052a0660055d092a0760095d0d2a08ce1a00ff390001020304050607012a600d5d112a0960115001570070cf7c563c5d0021fb62d006530a5d042144530b5d0821fb530c5d0c530d5d10530e51053a0aa005553f017f51063a0ba005553f450900ff390001020304050607012b017f51073a0ca005553f017f51083a0da005553f017f51093a0ea004553f017f62d006555a1955580a555900555722508657577c71bf5080010062d006535950f26400ff390001020304050607012c00090a5358555723508657577c71bf62d006555801555939555720508657577d71bf62d006555a1955580a555900555714508657577c71bf5080010062d0065338f100ff390001020304050607012d595000090a5358555715508657577c71bf62d006555801555939555712508657577d71bf62d006555a1955580a55590055571e508657577c71bf5080010062d0766e00ff390001020304050607012e0653595000090a535855571f508657577c71bf62d00655580155593955571c508657577d71bf62d006555a1955580a55590055571a508657577c71bf50800100addd00ff390001020304050607012f62d00653595000090a535855571b508657577c71bf62d006555801555939555718508657577d71bf70cf62d00153343c34e4c0e75700500a4b02344b090060d3583400ff39000102030405060701305200533757f450094b02344b090060d35200533657e850094b02344b090060d3520053355137a09551363900b0183c3500b0135700500a4b02344b090060d356654f00ff390001020304050607013100007d4cbc3900a0745135a01b5700500a4b02344b090060d351376d6d6d6d6d210754007d4cbc513770fb6d3a36a0037204d03157f450094b02344b090060d30c9e00ff3900010203040506070132513670fb6d533851366d6d6d211f023854005700500a4b02344b090060d35600007d4cbc5700500a4b02344b090060d351376d6d6d6d6d6d210354005700500a12ab00ff39000102030405060701334b02344b090060d3520008570450084b02344b090060d31854007f081091217c5bb27c5c0750070850000850ff08087c5c1638fc62c80b62ca3b43d60162cd00573600ff3900010203040506070134572062cf0079bffb41d6fe20187f081043d601407c4dee20187f70cf08105df70870fe5dc8a00590f6801362d00071014070fe62e3385108bff541d6fe90c118e55300ff39000102030405060701352101a003710120187f711043ec0270cf62da7f43e0807f41e07f62da7f7f3921d00c41d6ef41e07f62c80b800a62c80043d61043e0807f500049c8ffb00a62d0f26e00ff3900010203040506070136005108a00a800649c901a00350017f904149c8ffa00860cd5b60cf80045b3ffc90457f71404f52fd59fb9fe34f52fd74a00559fc9fd9703f71807f90025b7f90818d00ff39000102030405060701371149c8ffa005904a80063efc5c3efc90167f62d00153fc5dd653fd43d60151fc62d40762d5077f0851fd60d6187f62d0002e0aa0510a600471104304a070cf7f93b200ff3900010203040506070138711041045f70cf62d0002e0aa0510a60047f60cd5df70870fe5dcf5c5dcf7e49c901bffc41d6fe7f62d00155a7003905c003500553a462d30150005704549654d23100ff39000102030405060701399b79dffa3ca402c08853a253a05fa3a206a3035fa1a076a162d30658a2529553a558a33b95c00513958005529512a553a562d30658a275529553a658a3753b9537fc00ff390001020304050607013ac00513958005529512a653a650033aa5c0283aa6c0243ca502d00c62d30158a0779b58a1779b3ca602d00c62d30158a0779658a1779655a70106a30376a151a125d900ff390001020304050607013b3aa4cf9506a20376a051a0743aa4cf7e51a7703f71807f62d00162d4003906c003500553ef3906d05651efa05255f5c855f20051f23aefd04250033ef553e83e19c200ff390001020304050607013cf553e96ee86ee96ee86ee96ee86ee951e958f262d30f54053ef553e83ef553e96ee86ee96ee86ee96ee86ee951e962d30f540006f50476f28fba51efb00655eef88100ff390001020304050607013d0182e455ee0051eda00539ffb03c55f20051f23aefd02f5c62d30f520062d30f540a62d30f520562d30f540f51f26464645c62d30076ee51ee54c456c50056c62be800ff390001020304050607013e0076f28fcd7aee829e3ced04d0063cef04c23151ed3aefc0ea62d30f58ed79c0065614ff8ff955f20055f50051f23aefd03155f30051f33aedd0245c62d30f48c82300ff390001020304050607013f140fa0175ff1f25ff0f395b553f850083af8c007957976f5800576f38fd876f28fcb51ed12f53902a0053903b039941a94a493a751ef12f553f255f40051f43a92b800ff3900010203040506070140f2d1d451f46402f45c62d306528253f658f462d30652926403925c62d306528b933276f48fd855f20051f23aefd1a85c62d30f4814f0a04755f30055f4ff55f935ff00ff39000102030405060701410051f33aedd02b5c62d30f48140fa01e5ff1f25ff0f3952953fa3cf900b00753f95af480093af9d00553f95af476f38fd13cf4ffa0095ff1f25ff0f494d176f2625a00ff39000102030405060701428fa891b962d30f58ef79c0065614ff8ff955f20055f50051f23aedd03155f30051f33aefd0245c62d30f4814f0a0175ff1f35ff0f294ca53f850083af8c0079496c300ff39000102030405060701438e76f5800576f38fd876f28fcb51ef12f53904d04f51ed12f53900a0473904d04308932693b091ab1853f255f40051f43af2d08c58f462d30652926403925c623d1200ff3900010203040506070144d306528253f651f46402f45c62d306528b5c62d30f2714f058f627140f923576f48fcc55f20051f23aedd0545c62d30f48140fa04755f4ff55f90055f30051f3e15b00ff39000102030405060701453aefd02b5c62d30f4814f0a01e5ff1f35ff0f2942c3cf900b00853f95ff4f3800a3af9d00653f95ff4f376f38fd13cf4ffa0095ff1f45ff0f293d476f28fa851330000ff3900010203040506070146ef12edc05253f255f30051f33aefd0475c62d30f521421f039f0b01e1051ee90b453ee2062d306545f5b645c62d3065664005665007af2800751f2b003801876c32100ff3900010203040506070147f38fc855f50092ce51ed3aefc00591cb8005906990bd55f20051f23aefd04864646453f358f262d306525f58f362d30054c458f262d30f520062d30f540a62d309ae00ff39000102030405060701480f520562d30f540f5b645c62d306526508526458f362d30054c51854c677c60fc50076f28fb451ef3906d00a51efa0065fedef800455ed00703f71807f62d300f38300ff39000102030405060701495ff2ed51f23aefd00c6464645c56c40076f28ff07f62d300743900b0027453f73906c00455f7015ff6f755fa0051fa3aefd0116464645c52c43af7b00376f77685a800ff390001020304050607014afa8feb51f73906c00455f70151f73af6bfd67f91ea51f190de51f23af9d0ae500053f453e953e851f43af0d01b90dd51f46402f402fa645c62d306526f04e95222e300ff390001020304050607014b6e0ce876f48fe151e93aeb51e81aead0755feae85febe958f179c01551f5b00962d306565f008ff262d3065692ff8fea55f40051f43af0d01d909151f5b00a513a1400ff390001020304050607014cf45ff6fa904e800a58f451fa62d306549276f48fdf51f5b02d5fecee58f179c02562d306525fbff71051ec9f2853ec2062d306545f5b08645c62d30656650056b00100ff390001020304050607014d6400208fda76f206f3038f4e51f5b0045feeec7f6464645c62d30052c60852c50852c462d30658f6545f5b645c62d3061854641854657f01885c507e2853f9501bd800ff390001020304050607014e0053f253f355eaff55ebff7f51f302f4018c5c507e09002853fa7f90e251f09fd651f23af9d063500053f453e953e851f43af1d0199fd56402fa02f4645c62d36c7b00ff390001020304050607014f06526f04e9526e0ce876f48fe351e93aeb51e81aead02c5feae85febe955f40051f43af1d01d9fa451f5b00a51fa5ff6f49f61800a58f462d30651fa549276f4697600ff39000102030405060701508fdf76f206f3038f997f55f30055f20051f23aefd02f5c62d30f4814f0a02262d30f1052000862d30f52050851f36402f35c62d30618548118548018548276f3d65100ff390001020304050607015176f28fcd55f30055f20051f23aedd02f5c62d30f48140fa02262d30f10520a0862d30f520f0851f36402f35c62d30618548a18548918548b76f376f28fcd7f5101a800ff3900010203040506070152f5b0095ff0ed5ff1ef800b5ff0ed14f05ff1ef14f17f9fe755f20055f30051f23af0d0ab55f40051f43af1d09b3cf500b01462d30f5c520053f662d30f58f252e87700ff39000102030405060701530a53f7801b62d30651f46402f45c528053f662d30651f26402f25c528953f790cd53f83cf500b01562d30f58f4520553f662d30f58f2520f53f7801b62d30651c53200ff3900010203040506070154f46402f45c528153f662d30651f26402f25c528a53f7909653f953fa909f100851f853f953fa909553fa5af91804fa180cf951f302f4645c62d30651f9546e5190c900ff3900010203040506070155fa546f76f48f6176f206f3038f517f51f06464645c62d30052c60852c50852c462d30658f1545f5b645c62d30618546418546562d30f58f02714f058f127140fa5f400ff39000102030405060701567f58f162d30f520053f658f062d30f520a53f7901953f858f162d30f520553f658f062d30f520f53f7900302f87f51f73af6c00512f6800551f612f77f12f957381b00ff39000102030405060701570847f901a00302fa6d6ef979bff45c51f97f62d30757ef5000540779dffc703f71807f62d30662d0010853fe6404fe509502fe5c1853fe62d000518e7862d001402c00ff390001020304050607015812fea01653fe5203540052045401520554027575757afebfee703f71807f4f5b11027f62d00055fa0062d50062d4004f5b010353f955f83a5006007f11044bd06b8300ff39000102030405060701590478c0093a8040791900dff97f3900a00570cf71105e0070cf7f70cf5dfc1106c00350007f610070cf7f9fb762d00051f8390da0413905b04751f93910c0053900ae00ff390001020304050607015a12c0453971c0053987c03d399cc00539a0c0353987c0053993c02d3993c005399cc02139c1a01d39c3a01939c4a01939c5a015800b51f93912c0053916c00950525300ff390001020304050607015b0180075002800350047f62d0005318558f8062d301518f5727543979dffc550e007c5eae7c631055190062d3015870526b70cf712060a570cf551e08551f80628ecc00ff390001020304050607015cd3015870523960fd7c62f85119575c7c616e43a408476e01a003710170cf7c67b57c680a5000531c531d532b532a57075b3d4400a01310645c522d042b0e2a000ecd00ff390001020304050607015d5118041d0e1c002079dfe662d3015870512b3a1d512a1a1cd006511f732539511f67217f2d39681f261f7f7a1ebf91767051197c627876193c1902cf6e7c5eeb494400ff390001020304050607015e760e3c0e14cf5b703f71807f62d00057ef55ec00500a283900b00576ec8007391fb00376ec79dfed51ec7f62d30662d00655df00570756e20056ea0879dff870f09300ff390001020304050607015f3f718070cf62fd0041a2ef62d00670cf71104104bf410cfb410cef4100df4110fb4110ef70cf7120438002438404438801438c0443900243940870cf7110410888c400ff3900010203040506070160f7410cf7410cdf41087f4110f74110df70cf7120438001438408438802438c0843900143940462d00670cf712062a560500060836087608b608f60936097609ba5ff00ff3900010203040506070161609f5da253d541a20343a20c5dc953d662c90062a33f55e10143a40855de0055dd00570770cf62d30655dc3f6bdcd01152e204de52ea0cdd500014de50081cdd84be00ff390001020304050607016279dfea68dd6ede68dd6ede68dd6ede55d90055d80055dbff55daff570755dc3f6bdcd03951de15e251dd1dea51d83beaa005c009800f51d93be2d00952e253d9f19900ff390001020304050607016352ea53d852ea3adaa005c009800f52e23adbd00952e253db52ea53da79dfc251d953de51d853dd51db14de51da1cdd68dd6ede68dd6ede68dd6ede68dd6ede3c311a00ff3900010203040506070164de0ec01c26dff82edf0155e0003cde1bc02e2edf023cde28c0262edf04802151dfa01762d000518eb01062d00676e03ce016c00c55df00800762d00655e00070f09900ff3900010203040506070165cf712049c401affc41a4f741c4fe5da853e25dab53e35dae53e45db153e55db453e65db753e75dba53e85dbd53e95da953ea5dac53eb5daf53ec5db253ed5db56e9600ff390001020304050607016653ee5db853ef5dbb53f05dbe53f17ae1dec870cf7110430440430c04430c1043002043100443101070cf71204180fd4184fb4188fe418cfb4190fd4194f762a3e58500ff39000102030405060701670070cf7110430808430c08430c2043088043100843102070cf71204180fe4184f74188fd418cf74190fe4194fb62a30070cf43a21062d00670cf712051d560a24f5a00ff390001020304050607016851d660c951df703f718062d00070cf7f62e338718070bf62d0015000530062d10250004e500057000879bffd62d10350004e500057000879bffd62d10450004ec74b00ff3900010203040506070169500057000879bffd62d10550004e500057ff0879bffd62d10650004e5000575e0879bffd62d00062d10f50194e7d5b1a4043e6024070cf711062e30270cf62e309d000ff390001020304050607016a3841ffef50804e62e3385dd50862d50055fa0140500655f83a7c0060404070cf711051fa60e870cf1860d555f80055f90070cf7110419ffe70cf62e33850194ec74d00ff390001020304050607016b62d10f62d30f62d00062d50062d40071807c7d3d70cf711062ec1043e30070cf62e00041fee743fe1070cf711062e05370cf62e2007d5a107f3030303030303016ec00ff390001020304050607016c030910160001000200010002000200010001010101010100010162d00155010062e3387c145871017c13f57c145962e3387c120062d00551ffa0097c2c887c1209d300ff390001020304050607016d41530162d00555ff0162d00151017c137e62d00151017c13b47d5b2e7d5b5c43e1017f41e1fe7f4323017f4123fe7f60217f60227f5d227f71404f38025d230880c200ff390001020304050607016e5d22085d205d225401500049f701a0035001540070fe4123fe18602218602318703f71807e5d205d227f7600d0045500ff7e62d00070cf711041045f4305a07071a500ff390001020304050607016fcf260a5f510a6004550800902f903440404040405000530270cf71104304a04305a070cf2e0aa0510a60047f62d000510121b026014f7f503b7f800441e07f4381c600ff3900010203040506070170e0807f43d6317f41e07f41d6fe7f41e07f7f41d6fe7f714062d0004f52fd530652fc530752fb530552fa5304703f71807f0810703f71805dd3085dd00862d000cf6300ff3900010203040506070171510460d32e018049d708a0092601f02e0100800849d720a00380a65101210ee0018011806780798047809680948092809080975dd821fe3976a00662d700808ac85600ff390001020304050607017249d801b00f5508022601f02e010262d71080775508012601f02e01065f0302510502035c520060d8760362d714805b5106783a03c00f510502035c520060d8764a5b00ff3900010203040506070173032e012060d862d704803f5dd83a06d02ba029530353022601f02e010480185107783a03c016510502035c5dd854002e01107603800162d710800f62d700800a434e00ff39000102030405060701742601f02e01005508001860d01860d320187e9880808c9c8c9c989c989c988484888890909494204080101020208040408010102040808040201062d3015759501afd00ff39000102030405060701750928543979dff9703f71807f62d00062d50155183957005010283f18753c1893bff6703f71807f62d00062d5015518395700500e283f18753c1893bff6703f7119fc00ff3900010203040506070176807f62d00062d5015518395700500c283f18753c1893bff6703f71807f62d00055200c5521145522ef5523035524fe5525035526fe55960b5597195598085516577900ff390001020304050607017718551705557100557200557378557401557505557801557604557702559904557b01557c08559500557d805512005511005178a008517658777c60b062d301571f0a00ff390001020304050607017859500928543979dff9703f71805dfc70cf711062760743e20870cf712062a40162c0003904d00443c8047c610070cf712043810e43850e43890e438d0e43910e85d700ff390001020304050607017943950e43990e439d0e70cf556904556b02556d06556c00507857007c60597130621b4070cf62a2107c7bda50017c609670cf62d3065704500054b079dffc703fcf6c00ff390001020304050607017a71807c610d7f000c1824303c4854606c7884909ca8b4c0ccd8e400020406080a0c0e10121416181a1c1e2022242662d00070cf7110510ef0605c510ef07b73534b6500ff390001020304050607017bbc5e0022bc610070cf7120510efe435c510efe5253bc5e002abc610070cf510effa4536f510effb253707f70cf7120510efe1f5c510efe2e7353bc5e0022bc612f2e00ff390001020304050607017c0070cf7110510ef0105c510ef02b53bc5e002abc610070cf7f0000000000000408080808080c0c0c0c10101010000408080c0c0c0c1010101001020810408004669d00ff390001020304050607017d0102102040010240800102408020400880040810200408102062d000556c005175918b517358727c605951747c609670cf71205000608060846088608c609060303200ff390001020304050607017e946098609c60826086608a608e60926096609a609e60c0438104438504438904438d04439104439504439904439d0471307130621f00621b7062138770cf7110445b00ff390001020304050607017f55bc1f51bcff525c51bcff6d53195e002a1961007abcdfec70cf41a23f5512005511005178a008517658777c60b07f41e0fb7130411bbf70cf71204181fd41853f5200ff3900010203040506070180fd4189fd418dfd4191fd4195fd4199fd419dfd70cf41a2ef7c611970cf711041e2f770cf7f7c610070cf711043e2087130431b4070cf71204381024385024389b74300ff390001020304050607018102438d02439102439502439902439d0270cf43a2107c610d7f62d000531d5a1c536a5b2101a0062e6d018004266dfe681c6e1d511d7870cf712060c970cf7c7bae3200ff3900010203040506070182bc7f62d00053735a729fce7f60fd7f00040c1c3c7cfc62d00053107610fff0266b032c6b7c7bbc7f62d00053749fe77f62d00053765a7790017f62d000085a108cef00ff39000102030405060701835512ff55110178a00a0612ff0e110178bff8511068116e1278dffa16127f1e110018786464266b032c6b7c7bbc7f62d0007853697c7bbc7f62d00053759fef7f2a2c00ff390001020304050607018470cf712062a70962a74970cf7f70cf712049c808affc70cf7f70cf712062a70970cf7f70cf712062a78970cf7f62d0005513009708703f71807f62d000551302f8c900ff390001020304050607018596fb703f71807f62d00055130496ee703f71807f41a2ef7f43a2107f57ef500a2821e0b00779dff750007f50017f70cf711064e0018009807580e180ed80f9412f3800ff390001020304050607018604bf410cfb410cef4100df4110fb4110ef70cf71205df7536e70fe43800252016083063c012e440143840452046087063d042e45014388015206608b063e062e415d00ff39000102030405060701874601438c045200608f063f002e4701439002520860930640082e4801439408520a609706410a2e490143a33f7f4108f7410cf7410cdf41087f4110f74110df70fcd400ff3900010203040506070188cf71205df7536e70fe43800152026083063c022e440143840852056087063d052e45014388025207608b063e072e4601438c085203608f063f032e4701439001dc9500ff3900010203040506070189520960930640092e4801439404520b609706410b2e490143a33f7f70cf71205df7536e70fe43a3007f70cf71205df7536e70fe43a3007f7f70cf711064e00180252800ff390001020304050607018a098034805f8066806d430440430c04430c1043002043100443101070cf71204180fd4184fb4188fe418cfb4190fd4194f762a3008040430808430c08430c20435d9900ff390001020304050607018b088043100843102070cf71204180fe4184f74188fd418cf74190fe4194fb62a300801370cf712062a300800a70cf712062a300800170cf7f62d3005707524454528400ff390001020304050607018c54523c544c516f564400543c79dfef7f62d50062d300586f55bc5c500a28211f3fbc753cbc68bff47f62d50062d300586f55bc5c501128211f3fbc753cbc68cf9e1d00ff390001020304050607018df47f62d50062d300586f55bc5c500f28211f3fbc753cbc68cff47f62d50062d300586f55bc5c500d28211f3fbc753cbc68cff47f5000538453855381537e537fd99400ff390001020304050607018e5380538362d0005379537a5707471602b0c762d3005b3d5400a05310645c522c532a522d532b51106e2a6e2b78dffa5112142b51111c2aa00ed006552b008004395500ff390001020304050607018f552bff552a00512b531b2010524c5c62d30a512b73540062d30e1300c007390bd00b800539f6c0050479767a2079dfa3517a477980a003767968793903c01747a93600ff39000102030405060701907980a003767968793905c00a477980a00376796879570762d3003d5400a03610524c5c62d30a5200531b471610a01b51791500d00b477980b00e560000800947304500ff39000102030405060701917980a0045600ff520073532b5b7c6d7f7c6e172079dfc17f62d3005b3d5400a03f10645c522c532a522d532b51106e2a6e2b78dffa5112142b51111c2aa00ed0242e00ff390001020304050607019206552b008004552bff552a00512b531b2010524c7c6d7f2062d30654c5768179dfb7570755840055850062d3003d5400a05b1062d300524c5c62d30b52002062c77500ff3900010203040506070193d30654cd62d30648cd80a00656bdff800456bd0048c580a00a13c554b51fbdff800813c554b51fbd0048bd80b00f52bda003800552b5a009767e8009767f800573ce00ff3900010203040506070194767e767f52b5048552bd0c8479df9c3c84ffb00e3c85f9c009558400558500800d68846e8568846e8568846e85478580a00c3684ff3685ff76850e84003c8517b95b00ff3900010203040506070195d010168104517f3a81d04f517e3a81d0495580005582008233570762d3003d5400a03062d30652cd538548cd80a0065584ff800455840052c548c580a0080485941200ff39000102030405060701960e84ff800604850e840068846e85518554c579dfc78fbb81f35185afbd558000570762d3003d5400a01162d30652c548c580b0073914c003768079dfe65585007de500ff3900010203040506070197558400570762d3003d5400a02762d3065180a0183903d01452c548c580b00d3914c00952b5048552bd0c8452b5048552bd0c8479dfd03c84ffb00e3c85f9c009a53600ff3900010203040506070198558400558500800d68846e8568846e8568846e8551855382a172478480b0038067570755847f5585ff62d3003d5400a03f62d306478480b01848bd80b02a52bd70cd00ff39000102030405060701993a84a005c022802852b53a85c01a802048bd80a01b52bd3a84a005c00b801152b53a85c003800952bd538452b5538579dfb8478480a00c3c84ffb07151823a858b0400ff390001020304050607019ad06b5f82858066570755848055850162d3003d5400a03f62d306478480b01848bd80b03251843bbda005c022802851853bb5c01a802048bd80a01351843bbda0549700ff390001020304050607019b05c00b801151853bb5c003800952bd538452b5538579dfb8478480b00b5184b00c51823a85c0065f82858001478280b00b3c820ac00f55820a800a50f63a82c0e6bc00ff390001020304050607019c045582f6570762d3003d5400a03e62d306478280a00848bd80b016802f48bd80a003802852bdb01651823bb5c01080143dbdffc00952b53a82c00380075182056cc900ff390001020304050607019dc580095183b00552cd54c579dfb976833c8304d037570762d3003d5400a02862d30652cd48cd80a00656bdff800456bd0048c580a00a13c554b51fbdff8008139b2800ff390001020304050607019ec554b51fbd0079dfcf8e33570762d3003d5400a01d62d30652c510538162d300524c5c518162d30b540062d30a7c6e172079dfda7f62d00070cf712049c401af0e0f00ff390001020304050607019ffc41a4f741c4fe5da8532d5da9532c5dab532f5dac532e5dae53315daf53305db153335db253325db453355db553345db753375db853365dba53395dbb53385d509400ff39000102030405060701a0bd533b5dbe533a70cf7f62d30057075b3d4400a02510645c51106f2c6f2d78dffa5112152d51111d2ca00ed006562d008004562dff562c002079dfd47f550e00ab4b00ff39000102030405060701a1558b01550f007c5eae62d000511453153c1401a010c0123c1403b0059afd800b9ae080079ac380039aa6587062d301523960fd526b70cf712060a570cf9a795004fe00ff39000102030405060701a200575c7c616e43a408476e01a003710170cf510ea0059adc510e9f19500099d862d3015870523a60fd526c70cf712060a570cf9a435001575c7c616e43a4084764bf00ff39000102030405060701a36e01a003710170cf9aaa9ee9500199a87c5eeb760e3c0e14cf6d62d3009a199a937c6afe558b007f43e0087f41e0f77f62e60462d0005a275328100851290871213a00ff39000102030405060701a44038034f500054fe54fd010854ff48fc01a00952fb05fe52fa0dfd6ffd6ffe6ffc7bffbfea52fc60e852fe60e762e60062e60138fa703f71807f5df70870fe57448100ff39000102030405060701a5f0500062e60462e80162e70062e60062e60162daf749da08affc62daf708282828282828282828282828282851001849da08b0044080057462daf779bfe049da142200ff39000102030405060701a608a0027462e60460e862e70062e60062e60162d00053295527005528017e5df70870fe62d00051b858b77e5df70870fe62d00051b458b37e5df70870fe62d000ca8f00ff39000102030405060701a751b658b57e5df70870fe62d00051ba58b97e0808104f5df7714054fd703f7180201870fe62d00060d351b4540151b3540051b6540351b5540251b8540551b754c28000ff39000102030405060701a80451ba540751b95406703f71807e0808104f5df7714054fd703f7180201870fe62d00053b85ab77e0808104f5df7714054fd703f7180201870fe62d00053b45a61bf00ff39000102030405060701a9b37e0808104f5df7714054fd703f7180201870fe62d00053b65ab57e0808104f5df7714054fd703f7180201870fe62d00053ba5ab97e0808104f5df7714054fda44600ff39000102030405060701aa703f7180201870fe62d00060d3520153b4520053b3520353b6520253b5520553b8520453b7520753ba520653b9703f71807e0e1e3d7a07030000070e1e3d0301224300ff39000102030405060701ab00001e3d7af60e070100714062d00053184f70cf71105de02107085dfe70cf21182b00ffcd5319185819282828282828282879dff67a18bff0703f71807f9011f9f200ff39000102030405060701ac558c03518c901a768c3c8c15cff690647f62d50662d000558895558e005587017f62d30a62d50662d000110253195187022053875386551801588652003a97c0ab5700ff39000102030405060701ad243b0dc0203b0cc01c3b0bc0183b01c014783bffc00f3bf5c00b3bf4c0073bf3c0039182768676185120783a18bfcb703f71807f62d30a62d50662d0005586010b1800ff39000102030405060701ae551801551900588652003a97c0183b0dc0143b0cc0103b0bc00c3b01c008783bffc0039141768676185120783a18bfd755180151217853195122122074745386ca9700ff39000102030405060701af588652003a97c0183b01c014783bffc00f3bf5c00b3bf4c0073bf3c0039107768676185120783a18bfd7512078531855190102205386588652003a97c0183b0c1d3e00ff39000102030405060701b0c0143b0bc010783bffc00b3bf4c0073bf3c00390d15120048676195121783a19bfd555180055190151205386588652003a97c0183b0dc0143b0cc0103b01c00c448d00ff39000102030405060701b1783bf5c0073bf4c003909b5120048676195121783a19bfd55000531853195586005c52003a97c00f3b0dc00b3b0cc0073b01c0039070551800512178531951228d2000ff39000102030405060701b212207453865c52003a97c0103b01c00c783bf5c0073bf4c003904b551900512078531853865c52003a97c0103b0cc00c3b0bc008783bffc003902b51215319517cff00ff39000102030405060701b320531851227a187a1953865c52003a97c010783bffc00b3bf4c0073bf3c0039005703f71807f511701033a8ec00f51193f8851183f8851863f88768e7f0562d01f4600ff39000102030405060701b4005116082616ef7c613a7c613a62d00018531657ef62d30c520073540062d309540079dff17c612d7c612d57ef62d30c520062d30e540062d30d56000062d3084fa700ff39000102030405060701b5540479dfe9703f71807f5b7c4be81062d30c5c520062d00862d3083b04c00da0191304390bc0137603800f530052041200c007390bc00376025b2062d0007f5cbc8200ff39000102030405060701b65113e0018018800880015b9fbd808862d30c512b540062d30c5400807a62d30c512b73531a471607b00d62d30c540062d30c5400805c471602a0553c8d00a01ee4d300ff39000102030405060701b7511a62d309540062d30c540062d30e1300d003500062d30b540062d30c52000862d3093b00d0095318520053198007531952005318185400511a62d30c54003a0b2200ff39000102030405060701b819d003531951193a18d00351188003540062d30e13007f5318471880a01539f6d004550f0162d30a5600003c8e00b03a801662d30a081105d00350005400183a68dd00ff39000102030405060701b996d027518eb02362d30e5200531962d30c520012191e190062d30d03000e19005400511962d30e54005b9ede7f7f7c7a477f7c730b0862d00062d300518e6464973c00ff39000102030405060701ba641104c01b5c52c40852c654c41854c652c50852c754c51854c75b1108dfe7703f7180187f50ff3c9080c0113492769234910e910034900e9000538f5000531cc69b00ff39000102030405060701bb531d531e531f551a1865926b916b906b1f6b1e6b1d511f1a94511e1a93511d1900c00d531d5194141f51931c1e76927a1abfd750ff3c8f80c011349276923491c79e00ff39000102030405060701bc0e910034900e9000348f7f5000531c531d531e531f90545192041d51910c1c904a5192041d51910c1c9040903e903c5192041d51910c1c90329030902e519204cead00ff39000102030405060701bd1d51910c1c90245192041d51910c1c901a901890165192041d51910c1c900c5192041d51910c1c9002900070fb6e1c6e1d6e1e6e1f7f5000531c531d531e531fe5dc00ff39000102030405060701be9fe99fe79fe59fe39fe19fdf5192041d51910c1c9fd59fd35192041d51910c1c9fc99fc75192041d51910c1c9fbd9fbb5192041d51910c1c9fb19faf5192041d56bf00ff39000102030405060701bf51910c1c9fa58fa462d0005318558f8055906055910062d30a501057ef540079dffc62d301518f5727543979dffc550e007c5eae55190062d30158705190546ba66000ff39000102030405060701c062d3015870518f5439551e80526b70cf712060a570cf62d3015870523960fd551f107c62f8516f01005c62d30a51197c616e43a408476e01a003710170cf7c675ccd00ff39000102030405060701c1b57c680a552a00552bff551c0762d300581c3d4400a02a523c08511c645c522d2062d30a3a18d006511f732500511f672d0052003a2ac003532a3a2bd003532b8e3200ff39000102030405060701c27a1cdfca681fdf9b511ea042479101b03d587062d301512b022a391fa030d006511e732539511e67217f2d39681e261e7f551c0762d300581c3d4400a00a523c3a8b00ff39000102030405060701c35c62d30a5600107a1cdfea8f4a479102b0323c2a1fc02d62d30158703d6b40a023176b20551c0762d30062d300581c3d4400a00a523c5c62d30a5600107a1cdf378600ff39000102030405060701c4ea8efe767051197c627876193c1902cee77c5eeb760e3c0e14ced7570062d3015693f556945f5695aa703f71807f62d000551899538f5a905591038e9a62d000b27d00ff39000102030405060701c5551899538f5590605591018e8a62d000551899558f8053905591028e7a08105dd0085dd3085dd4085dd508703f718062d0001860d51860d41860d31860d02018c9ac00ff39000102030405060701c67e08512804b451270cb3512804b651270cb5512804b851270cb7512804ba51270cb9180851be04c051bd0cbf4123fe5500005129602162dbfe432301187e3062862700ff39000102030405060701c7d00053f85df70821c0b00756010055f80051f8703f718060d355fd013cfd01b0ae70cf71105de00821f849fe08b00a49fe10b0092901800729028003290060e0b98e00ff39000102030405060701c870cf800165fd3cfd02b08465fd70cf711049e408a00570cf802070cf520053fa51fd3904b0690810500355f83a7c0060201853fd3cf800a00955ff0055fd108057cb00ff39000102030405060701c93765fd520053fa520253fb520160d4520553fc55fe5651fd3908b0330810500255f83a7c0060201853fd55ff013cf800a00455ff0065fd3cfd10b0131870cf712e7a00ff39000102030405060701ca1060e070cf65fd51ff3cfd20a004308ffe62d00062d50062d4007e30303062d00053f85df70821c0b00756010055f80051f8703f718060d3520253fb520160d5032500ff39000102030405060701cb52037453fd520453fe50006c006a6c006a6c006a6c006a6c006a6c006a6c006a0852005c1808283ffb1875b002747afeb0057afda00f3cfb00bfeb085dd57460174e00ff39000102030405060701ccd5188fe262d00062d5007e62d000518ea12955c3003c8e02c00455c3015f8a8e62d40662d500558e005589955588c43e8953193e8953183e8953863c1902c094720500ff39000102030405060701cd512111033a19c08c3c1802c087512011033a18c07f62d30a588652fe53a452ff53a5520053a6520153a7520253a85b12205c52fe539f52ff53a0520053a15201740a00ff39000102030405060701ce53a2520253a35b12205c52fe539a52ff539b5200539c5201539d5202539e518602205c52fe53a952ff53aa520053ab520153ac520253ad5b02205c52fe53ae52cebf00ff39000102030405060701cfff53af520053b0520153b1520253b2907180537c76bd906a51193901a017512111023a19a00f51183901a009512011023a18b0047c775b55c2005119a0155121318600ff39000102030405060701d0783a19a00e5118a01a5120783a18a01380145118a00a5120783a18a003800455c2017c77c9518e3a17c00550ff800c7c748a7a8a518abef8518e558a00703f71246d00ff39000102030405060701d1807f1055930051a002a10e930002a20e930002a50e930002a60e930002a70e930002aa0e930002ab0e930002ac0e930058953c9500a00970fb6e936d798ff73cb18800ff39000102030405060701d29300a00350ff53c1207f3cc301b02d62d306588e3db001a0235000539a539b539c539d539e539f53a353a453a853a953ad53ae53af53b053b153b262d50006888c3f00ff39000102030405060701d3035000538f53905392539362d3001051b25717039a0e930079dff953942051c180083c9300a00350ff3f8851b202ad0e900002a80e900002a30e9000029e0e906afc00ff39000102030405060701d400129a1e9000129f1e900012a41e900012a91e900012ae1e9000646b9002b10e900002ac0e900002a70e900002a20e9000029d0e9000129b1e900012a01e9000710b00ff39000102030405060701d512a51e900012aa1e900012af1e900053917c6ea5517d049251180c910e9000479080a00a5590005591005592007c6f76471608a03662d3004d88511c3b00c01e985a00ff39000102030405060701d6b009511d3b01a021c014511c3a23b007511d3a24a0137a1d1e1c00800c511c2a1da006761d0e1c004d88511c3a23c00bb013511d3a24c003b00b511c3f88511d853500ff39000102030405060701d73f88800951233f8851243f8850005390539251ae02af0e900002b00e900002b10e900002b20e9000129a1e9000129b1e9000129c1e9000129d1e9000129e1e90ec0400ff39000102030405060701d800646b9002a90e900002aa0e900002ab0e900002ac0e900002ad0e9000129f1e900012a01e900012a11e900012a21e900012a31e900053917c6ea55119069280b08d00ff39000102030405060701d90c910e9000479080a00a5590005591005592007c6f0b471608a03662d3004d88511c3b00c01eb009511d3b01a021c014511c3a25b007511d3a26a0137a1d1e1c7c2600ff39000102030405060701da00800c511c2a1da006761d0e1c004d88511c3a25c00bb013511d3a26c003b00b511c3f88511d3f88800951253f8851263f8862d30a768e518e55c1007f559200298100ff39000102030405060701db5f91190691fe5f90180690fe518608512014861486168602558f067a8f518fa074479180b0445121783a91c03d5593067a935193a04f479080b01e5120783a90e6fc00ff39000102030405060701dcc017588662d30a5200589262d300549a7692769076868fd9589262d300569a00755a92769076868fc8589262d3005000549a75549a75549a75549a75549a755a46bd00ff39000102030405060701dd9206860576915f90180690fe5120110504868f8862d30a1853867f62d3003c1901b0155705529a5f1c7c7c7a245495755b390abff1801b512111023a19b013577e2e00ff39000102030405060701de0f529a5f1c7c7c7a24549f755b3914bff13c1801b0175701529a5f1c7c7c7a2454995b01055c3915bfef801d512011023a18b0155703529a5f1c7c7c7a24549b61f500ff39000102030405060701df5b01055c3917bfef7f62d3005119b07f559a04559b10559c10559d10559e0451c2b02351a6a00d51a55f92a75f94a691f3539c51aba00f51aa5f92ac5f94ab918b4a00ff39000102030405060701e0e3539b539d570452a4531e529a531f7c7a0e50046e1e6e1f78bffa52a9141f1e1e00471e80a007551e00551f00471e7fa004551fff5f1c7b511f7c7a24549f6d3bab00ff39000102030405060701e16d6d211f549a6d217f059a79dfba512111013a19b07f55ae0455af1055b01055b11055b20451c2b02351a6a00d51a55f92a75f94a6916d53b051a1a00f51a05fc0b600ff39000102030405060701e292a25f94a1915d53af53b1570452a4531e52ae531f7c7a0e50046e1e6e1f78bffa529f141f1e1e00471e80a007551e00551f00471e7fa004551fff5f1c7b511fc6c300ff39000102030405060701e37c7a2454a96d6d6d211f54ae6d217f05ae79dfba3c1800b082559a04559f1055a41055a91055ae0451c2b02351a6a00d51a15f92ab5f94a690ea53a451a7a00fd6e400ff39000102030405060701e451a25f92ac5f94a790da539f53a95714529c531e529a531f7c7a0e50046e1e6e1f78bffa529d141f1e1e00471e80a007551e00551f00471e7fa004551fff5f1c935f00ff39000102030405060701e57b511f7c7a24549b6d6d6d211f549a6d217f059a5b11055cdfb7512011013a18b082559e0455a31055a81055ad1055b20451c2b02351a6a00d51a15f92ab5f94b3a000ff39000102030405060701e6a6906153a851a5a00f51a05f92aa5f94a5905153a353ad5714529c531e529e531f7c7a0e50046e1e6e1f78bffa529b141f1e1e00471e80a007551e00551f0047166700ff39000102030405060701e71e7fa004551fff5f1c7b511f7c7a24549d6d6d6d211f549e6d217f059e5b11055cdfb77f55910004920e910065926b9165926b9165926b9165926b915590005551de00ff39000102030405060701e893007c6ea551923910d00350107f121f559008471f01a003021e6d6e1f7a90bff3531e7f531f551e00471c30a00a651f6b1e041f0e1e00511c210fa008681e6ea58700ff39000102030405060701e91f78bffa511f7f62d0003c8e02c00e558a009009478a40a0047c6afe7f62d40662d30a500053865389531853195588953e88539a3e88539b3e88539c76195119793000ff39000102030405060701ea3a8ed11f3e88539d3e88539e3e88539f519a129dd003737453a0519b129ed003737453a151a0a0073902a003802d51a1a0053902b025519a3a9dc00ba011519c630500ff39000102030405060701eb122053a2800c519c022053a280045fa29c519b129e6714a2808d3ca002b0413ca101b03c519a3a9dc00ba011519c122053a2800c519c022053a280045fa29c518b5600ff39000102030405060701ec9b3a9ec00e58a25200793b00d0107aa2800c58a25200753b00d00376a280483ca001b0413ca102b03c519b3a9ec008519c7853a28006519c7453a2519a3a9dc055eb00ff39000102030405060701ed0ba01151a2122053a0800c51a2022053a0800455a00058a2520058a03b00d0035aa280038f17589c520058a21300cf0d3a99df09589f520058a21300ceff3a9938b200ff39000102030405060701eedefb589c5200589f3b00d00a52000101558a4080060101558a4058a2540076868edb76185f19180689035189558895048851183a8eceba703f71807f62d00070fa3700ff39000102030405060701efcf7120516960a0516b60a2516a60a1516d60c7516c60a470cf7f62d00062d50062d40062d30055fa00500655f83a7c00603cf80db0153cf912a0153cf913a010cee000ff39000102030405060701f03cf914a00b3cf915a0063cf805b01270cf712062a6007130621b30431b4070cf7f2304212022006100fd00a000a100a200a300a800a7007c007a007b007900cad2e900ff39000102030405060701f13bd604cf00c800a900b700b0ccb10eb200b333b433b500b6406c006d006e006f00e600e900ec00e820eb00ee00e700ea00ed00ff23002020210722407600af00926a00ff39000102030405060701f2d100a100d300a300d000a000d200a200dc08e1ffe201dfffde02dd0099009c00d800d900da00db009e00ac00ffc100c200c3008000810082008300a800a900aa39b900ff39000102030405060701f3008400850086008700ab00ac00ad00880089008a008b00ae00af00b0008c008d008e008f00b100b200b3009000910092009300b400b500b6009400950096009754f000ff39000102030405060701f400b700b800b900980099009a009b00ba00bb00bc009c009d009e009f00bd00be00bf00a400c000ff11061202138714031b301c0019241a300a3c0b3cff550900865500ff39000102030405060701f5550aa0550b04550c00550d007c7d537c7ddb7f1070cf500008507c57217c7d8618500108507c57747c7d8618500208507c57ad7c7d8618500308507d57287c7d2fa800ff39000102030405060701f6861870cf207f7140380210084f52f9640864030054fc18182070cf62e30010082839ffa0304f54fd52fc3900a0131106e00170cf7110800970cf712080037130671900ff39000102030405060701f718207509001008284f59fd610018207509008fc638fc703f71807f70cf62000070cf71106200ff6201fb70cf6202006201006204a070cf71106204ec6205f770661800ff39000102030405060701f8cf62060062050062080470cf71106208ff6209ff70cf620a00620900620c0070cf7110620cff620dff70cf620e00620d0062100070cf71106210ff6211ff70cf30ad00ff39000102030405060701f962120062110070cf7f0000000000000408080808080c0c0c0c10101010000408080c0c0c0c101010100102081040800401021020400102408001024080204008055800ff39000102030405060701fa80040810200408102001020600010201000200020102000101020002010030303030303030303030303030303030303030303030303030303030303030303030733500ff39000102030405060701fb30303030303030303030303030303030303030303030303030303030303030303030303030303030303030303030303030303030303030303030303030303030005000ff39000102030405060701fc30303030303030303030303030303030303030303030303030303030303030303030303030303030303030303030303030303030303030303030303030303030005100ff39000102030405060701fd30303030303030303030303030303030303030303030303030303030303030303030303030303030303030303030303030303030303030303030303030303030005200ff39000102030405060701fe30303030303030303030303030303030303030303030303030303030303030303030303030303030303030303030303030303030303030303030303030303030005300ff39000102030405060701ff30303030303030303030303030303030303030303030303030303030303030303030303030303030303030303030303030303030303030303030303030303030005400ff390001020304050607001e17cb303030303030303030303030303030303030303030303030303030303030022316a40000180b140c00303030303030303030303030303030303030303030949a00ff390001020304050607001f3030303030303030303030303030303030303030303030303030303030303030303030303030303030303030303030303030303030303030303018234b62b49d19a500ff3b0001020304050607];
					fw_version = [16a40000180b140c00];
					type = <0x0000001b>;
				};

				Framework@0 {
					abs_params = [35000e00f1030000000036000a00b003000000003a000000ff00000000003200000014000000000039000000040000000000];
					class = [4672616d65776f726b00];
					enable_touch_vkeys = <0x01>;
					type = <0x0000001c>;
					vkey_map = [006b054100680067011405410068006701bc0541006800670265054100680067];
				};

				IC@0 {
					class = <0x494300>;
					i2c_addrs = [3b3b];
					tsett1 = [00000000];
					tsett1_tag = <0x03>;
					tsett2 = [00000000000100ff00];
					tsett2_tag = <0x06>;
					tsett3 = [0001020304050607];
					tsett_list = [010203];
					type = <0x0000001a>;
				};
			};
		};

		I2C@4 {
			class = <0x49324300>;
			type = <0x001e0003>;

			I2C,Board@1 {
				1p8_via_gpio = <0x01>;
				class = [4f563838323000];
				gpio_avdd_en = <0x00000036>;
				gpio_dig_en = <0x0000003a>;
				gpio_pwd = <0x0000005f>;
				gpio_reset = <0x00000061>;
				i2c,address = <0x00000036>;
				i2c,type = [6f763838323000];
				type = <0x00290000>;
			};

			I2C,Board@2 {
				class = [4d54394d31313400];
				gpio_avdd_en = <0x00000052>;
				gpio_dig_en = <0x00000059>;
				gpio_reset = <0x0000004c>;
				i2c,address = <0x00000048>;
				i2c,type = [6d74396d31313400];
				mclk_freq = <0x0124f800>;
				type = <0x00280000>;
			};

			I2C,Board@3 {
				class = [4c4d3335353600];
				current_cntrl_reg_val = <0x2b>;
				enable_gpio = <0x00000002>;
				i2c,address = <0x00000063>;
				i2c,type = [6c6d333535365f6c656400];
				type = <0x000b0006>;
			};

			LEDLM3559@0 {
				class = [4c45444c4d3335353900];
				enable_gpio = <0x00000002>;
				i2c,address = <0x00000053>;
				i2c,type = [6c6d333535395f6c656400];
				type = <0x000b0003>;
			};
		};

		IOMUX@0 {
			class = [494f4d555800];
			settings = [00000101010002000000010100020004000200000000040102000000000500010303000005010101030000140001030001001401010300010015000103000100150101030001005d0000000000005d0100000000];
			type = <0x001e000f>;
		};

		PowerIC@0 {
			chg-hot-temp = <0x36>;
			chg-hot-temp-offset = <0x06>;
			class = [506f776572494300];
			type = <0x001e0004>;

			LED@0 {
				class = [5175616c636f6d6d504d383932314c454400];
				default_trigger = [6e6f6e6500];
				index = <0x00000001>;
				led_name = [627574746f6e2d6261636b6c6967687400];
				type = <0x001e000e>;
			};
		};

		Vibrator@0 {
			class = [5669627261746f7200];
			max = <0x01c9c380>;
			min = <0x00003a98>;
			pwm = [00004e1f000000010000000100000001000061a7000080e8000080e800004e20000080e700009c4000009c40000061a800009c3f0000cb200000cb20000080e80000ea600000ea600000ea6000009c4001ba814100009c4000009a4c00009c4001ba852900002710000027100000138801c9c38000009c4000009a4c00000000];
			regulator = [383932315f6c313600];
			type = <0x00000017>;
			vib_dir = [0000001f00000001ffffffff0000004f];
			vib_en = [0000001f00000001ffffffff0000002f];
		};
	};
};

/ {

	mmi,revision = "p3";

};
